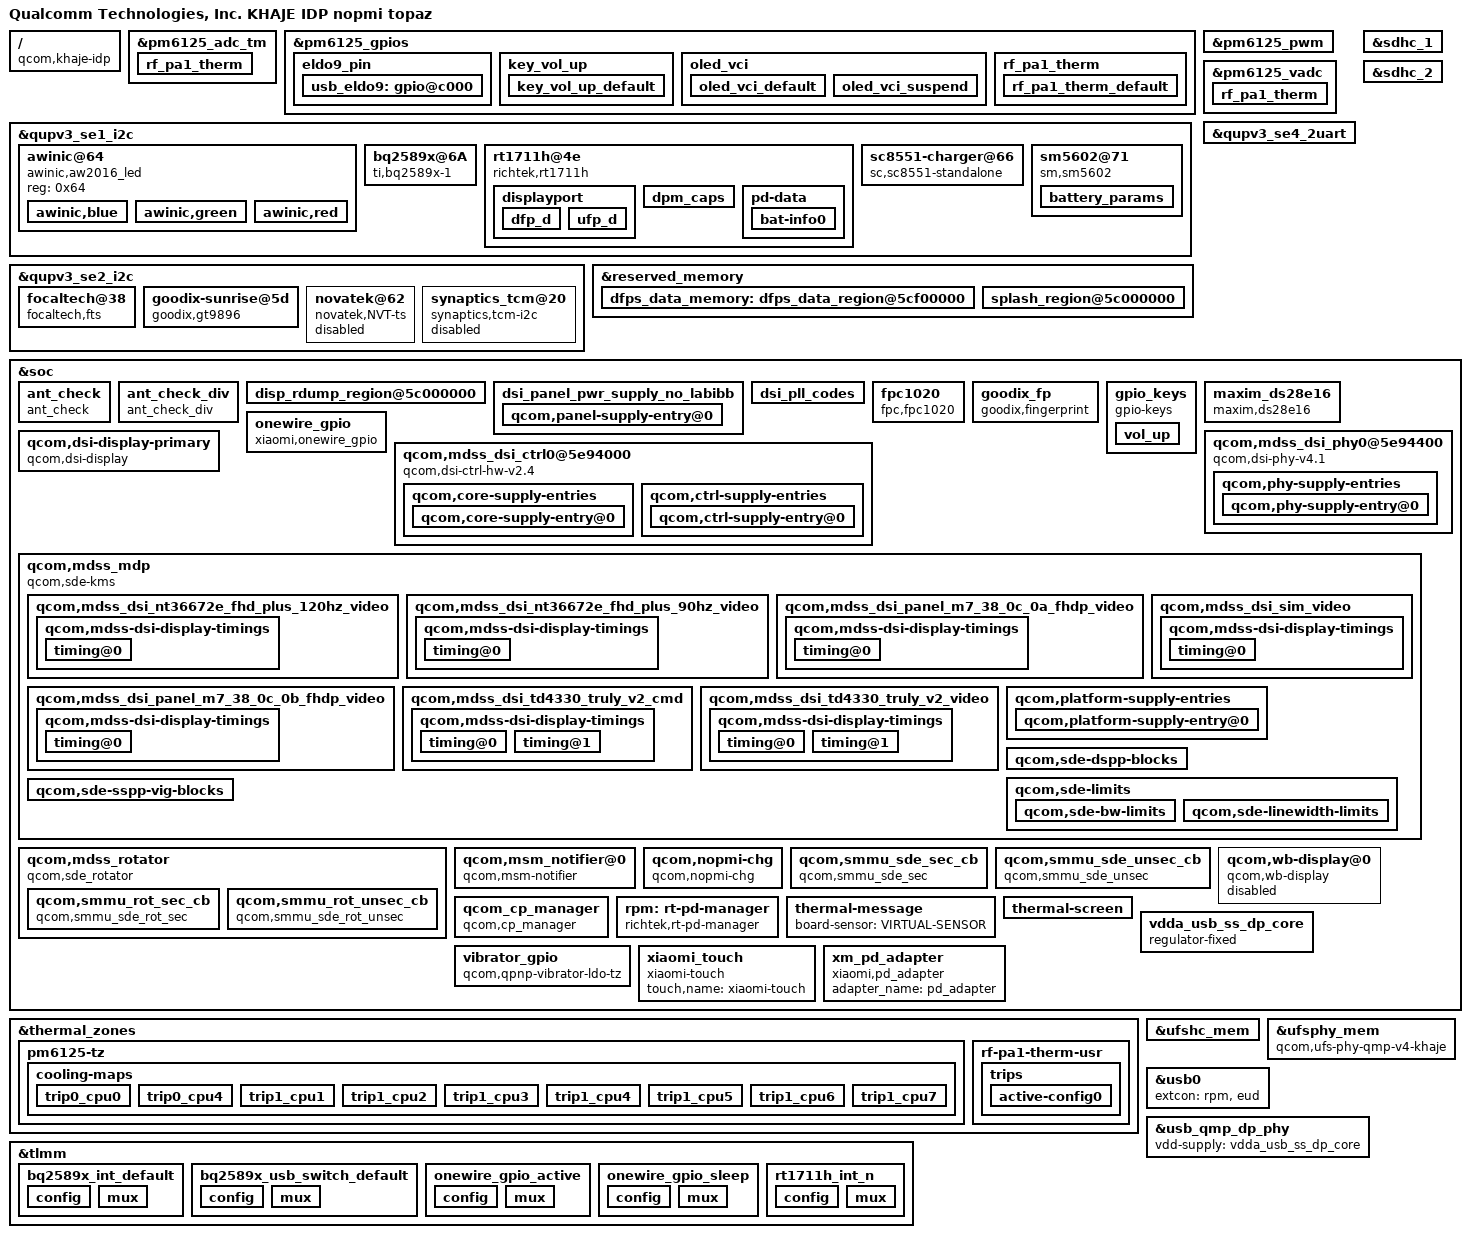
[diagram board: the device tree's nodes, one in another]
/dts-v1/;
// version: 17
// last_comp_version: 16
// boot_cpuid_phys: 0x0

/ {
    compatible = "qcom,khaje-idp", "qcom,khaje", "qcom,idp";
    model = "Qualcomm Technologies, Inc. KHAJE IDP nopmi topaz";
    qcom,board-id = <0x30022 0x0>;
    qcom,msm-id = <0x24A 0x10000>;
    qcom,pmic-id = <0x2D 0x0 0x0 0x0>;
};

&pm6125_adc_tm {
    status = "ok";
    rf_pa1_therm {
        io-channels = <&pm6125_vadc 0x55>;
        qcom,hw-settle-time-us = <0xC8>;
        qcom,ratiometric;
        reg = <0x3>;
    };
};

&pm6125_gpios {
    eldo9_pin {
        usb_eldo9: gpio@c000 {
            bias-disable;
            function = "normal";
            output-high;
            pins = "gpio1";
            power-source = <0x0>;
            qcom,drive-strength = <0x2>;
        };
    };
    key_vol_up {
        key_vol_up_default: key_vol_up_default {
            bias-pull-up;
            function = "normal";
            input-enable;
            pins = "gpio5";
            power-source = <0x0>;
        };
    };
    oled_vci {
        oled_vci_default: oled_vci_default {
            bias-disable;
            function = "normal";
            input-disable;
            output-high;
            pins = "gpio9";
            power-source = <0x0>;
            qcom,drive-strength = <0x2>;
        };
        oled_vci_suspend: oled_vci_suspend {
            bias-disable;
            function = "normal";
            input-disable;
            output-low;
            pins = "gpio9";
            power-source = <0x0>;
            qcom,drive-strength = <0x2>;
        };
    };
    rf_pa1_therm {
        rf_pa1_therm_default: rf_pa1_therm_default {
            bias-high-impedance;
            pins = "gpio7";
        };
    };
};

&pm6125_pwm {
    status = "ok";
};

&pm6125_vadc {
    pinctrl-0 = <&camera_therm_default &emmc_therm_default &rf_pa1_therm_default>;
    rf_pa1_therm {
        label = "rf_pa1_therm";
        qcom,hw-settle-time = <0xC8>;
        qcom,pre-scaling = <0x1 0x1>;
        qcom,ratiometric;
        reg = <0x55>;
    };
};

&qupv3_se1_i2c {
    #address-cells = <0x1>;
    #size-cells = <0x0>;
    status = "ok";
    awinic@64 {
        compatible = "awinic,aw2016_led";
        reg = <0x64>;
        awinic,blue {
            awinic,fall-time-ms = <0x6>;
            awinic,hold-time-ms = <0x0>;
            awinic,id = <0x2>;
            awinic,imax = <0x2>;
            awinic,led-current = <0x3>;
            awinic,max-brightness = <0xFF>;
            awinic,name = "blue";
            awinic,off-time-ms = <0x4>;
            awinic,rise-time-ms = <0x6>;
        };
        awinic,green {
            awinic,fall-time-ms = <0x6>;
            awinic,hold-time-ms = <0x0>;
            awinic,id = <0x1>;
            awinic,imax = <0x2>;
            awinic,led-current = <0x3>;
            awinic,max-brightness = <0xFF>;
            awinic,name = "green";
            awinic,off-time-ms = <0x4>;
            awinic,rise-time-ms = <0x6>;
        };
        awinic,red {
            awinic,fall-time-ms = <0x6>;
            awinic,hold-time-ms = <0x0>;
            awinic,id = <0x0>;
            awinic,imax = <0x2>;
            awinic,led-current = <0x3>;
            awinic,max-brightness = <0xFF>;
            awinic,name = "red";
            awinic,off-time-ms = <0x4>;
            awinic,rise-time-ms = <0x6>;
        };
    };
    bq2589x@6A {
        #address-cells = <0x1>;
        #io-channel-cells = <0x1>;
        #size-cells = <0x0>;
        compatible = "ti,bq2589x-1";
        interrupt-parent = <&tlmm>;
        interrupts = <0x69 0x0>;
        intr-gpio = <&tlmm 0x69 0x0>;
        io-channel-names = "ds_chip_ok", "fastcharge_mode", "fg_monitor_work", "mtbf_cur", "usb_real_type", "pd_active", "typec_cc_orientation", "typec_mode", "ffc_disable";
        io-channels = <&maxim_ds28e16 0x8D &sm5602 0xA4 &sm5602 0xAC &nopmi_chg 0x90 &nopmi_chg 0xA &nopmi_chg 0x4 &nopmi_chg 0x3 &nopmi_chg 0x1 &nopmi_chg 0xAB>;
        pinctrl-0 = <&bq2589x_int_default>;
        pinctrl-names = "default";
        reg = <0x6A>;
        ti,bq2589x,charge-current = <0x7D0>;
        ti,bq2589x,charge-current-1000 = <0x3E8>;
        ti,bq2589x,charge-current-1500 = <0x5DC>;
        ti,bq2589x,charge-current-3500 = <0xDAC>;
        ti,bq2589x,charge-current-500 = <0x1F4>;
        ti,bq2589x,charge-voltage = <0x1162>;
        ti,bq2589x,enable-auto-dpdm;
        ti,bq2589x,enable-ico;
        ti,bq2589x,enable-termination;
        ti,bq2589x,input-current-2000 = <0x7D0>;
        ti,bq2589x,term-current = <0x100>;
        ti,bq2589x,use-absolute-vindpm;
        ti,bq2589x,vbat-min-volt-to-tuneup = <0xBB8>;
        ti,bq2589x,vbus-volt-high-level = <0x21FC>;
        ti,bq2589x,vbus-volt-low-level = <0x1130>;
        usb-switch1 = <&tlmm 0x1F 0x0>;
    };
    rt1711h@4e {
        #io-channel-cells = <0x1>;
        compatible = "richtek,rt1711h";
        pinctrl-0 = <&rt1711h_int_n>;
        pinctrl-names = "default";
        reg = <0x4E>;
        rt-tcpc,name = "type_c_port0";
        rt-tcpc,role_def = <0x4>;
        rt-tcpc,rp_level = <0x0>;
        rt-tcpc,vconn_supply = <0x1>;
        rt1711pd,intr_gpio = <&tlmm 0x5D 0x0>;
        rt1711pd,intr_gpio_num = <0x5D>;
        status = "okay";
        tcpc-dual,supported_modes = <0x0>;
        displayport {
            1st_connection = "dfp_d";
            2nd_connection = "dfp_d";
            signal,dp_v13;
            typec,receptacle;
            dfp_d {
                pin_assignment,mode_c;
                pin_assignment,mode_d;
                pin_assignment,mode_e;
            };
            ufp_d {
            };
        };
        dpm_caps {
            attemp_discover_cable;
            attemp_discover_id;
            attemp_enter_dp_mode;
            dr_check = <0x0>;
            local_dr_data;
            local_dr_power;
            local_no_suspend;
            local_usb_comm;
            local_vconn_supply;
            pr_check = <0x0>;
        };
        pd-data {
            bat,nr = <0x1>;
            pd,charging_policy = <0x31>;
            pd,country_nr = <0x0>;
            pd,id-vdo-data = <0xD14029CF 0x0 0x17110000 0x61000000 0x0 0x41000000>;
            pd,id-vdo-size = <0x6>;
            pd,mfrs = "RichtekTCPC";
            pd,pid = <0x1711>;
            pd,sink-pdo-data = <0x190C8>;
            pd,sink-pdo-size = <0x1>;
            pd,source-cap-ext = [CF 29 11 17 00 00 00 00 00 00 00 00 00 00 00 00 00 00 00 00 00 00 00 02 00];
            pd,source-pdo-data = <0x19032>;
            pd,source-pdo-size = <0x1>;
            pd,vid = <0x29CF>;
            bat-info0 {
                bat,design_cap = <0xBB8>;
                bat,mfrs = "bat1";
                bat,pid = <0x1711>;
                bat,vid = <0x29CF>;
            };
        };
    };
    sc8551-charger@66 {
        #io-channel-cells = <0x1>;
        compatible = "sc,sc8551-standalone";
        irq-gpios = <&tlmm 0x54 0x0>;
        reg = <0x66>;
        sc,sc8551,ac-ovp-threshold = <0x11>;
        sc,sc8551,bat-ocp-alarm-threshold = <0x1D4C>;
        sc,sc8551,bat-ocp-threshold = <0x1F40>;
        sc,sc8551,bat-ovp-alarm-threshold = <0x1130>;
        sc,sc8551,bat-ovp-threshold = <0x11AD>;
        sc,sc8551,bat-therm-disable = <0x0>;
        sc,sc8551,bat-therm-threshold = <0x15>;
        sc,sc8551,bat-ucp-alarm-threshold = <0x7D0>;
        sc,sc8551,bus-ocp-alarm-threshold = <0xDAC>;
        sc,sc8551,bus-ocp-threshold = <0xEA6>;
        sc,sc8551,bus-ovp-alarm-threshold = <0x2AF8>;
        sc,sc8551,bus-ovp-threshold = <0x2EE0>;
        sc,sc8551,bus-therm-disable = <0x0>;
        sc,sc8551,bus-therm-threshold = <0x15>;
        sc,sc8551,die-therm-threshold = <0x7D>;
        sc,sc8551,sense-resistor-mohm = <0x5>;
    };
    sm5602@71 {
        #io-channel-cells = <0x1>;
        compatible = "sm,sm5602";
        io-channel-names = "ds_authen_result", "ds_romid", "ds_status", "ds_page0_data", "ds_chip_ok", "usb_real_type", "charging_enabled", "sc_battery_voltage", "ln_charging_enabled", "ln_battery_voltage", "charge_done";
        io-channels = <&maxim_ds28e16 0x84 &maxim_ds28e16 0x80 &maxim_ds28e16 0x81 &maxim_ds28e16 0x8A &maxim_ds28e16 0x8D &nopmi_chg 0xA &sc8551_standalone 0x76 &sc8551_standalone 0x96 &bq2589x 0x39>;
        reg = <0x71>;
        sm,aging_ctrl = <0x121>;
        sm,battery_table_num = <0x0>;
        sm,cycle_cfg = <0x7000>;
        sm,en_batt_det;
        sm,en_temp_ex;
        sm,fg_irq_set = <0x7FF>;
        sm,low_soc1 = <0x1>;
        sm,low_soc2 = <0xF>;
        sm,misc = <0x800>;
        sm,param_version = <0x5>;
        sm,rsns = <0x0>;
        sm,shutdown-delay-enable;
        sm,soc_decimal_rate = <0x0 0x26 0xA 0x23 0x14 0x21 0x1E 0x21 0x28 0x21 0x32 0x21 0x3C 0x21 0x46 0x1E 0x50 0x19 0x5A 0x14 0x5F 0xA>;
        sm,t_h_alarm_ex = <0x955F>;
        sm,t_h_alarm_in = <0x1>;
        sm,t_l_alarm_ex = <0xD632>;
        sm,t_l_alarm_in = <0x36>;
        sm,v_h_alarm = <0x1162>;
        sm,v_l_alarm = <0xD48>;
        battery_params {
            battery0,alpha = <0xCC>;
            battery0,battery_table0 = <0x1400 0x1B3D 0x1C5E 0x1D3A 0x1D80 0x1D8D 0x1D93 0x1DAA 0x1DFA 0x1E3E 0x1E77 0x1EB2 0x1F09 0x1F67 0x1FB3 0x1FE6 0x2046 0x20EB 0x21A1 0x2220 0x227A 0x2319 0x2360 0x24CC>;
            battery0,battery_table1 = <0x0 0x68 0x1F2 0x400 0x58A 0x798 0xAAC 0xCBA 0x1367 0x1B1A 0x22CD 0x2A80 0x3234 0x3756 0x39E7 0x3C78 0x419A 0x494E 0x5101 0x5623 0x59BB 0x60EB 0x6400 0x64E6>;
            battery0,battery_table2 = <0x141C 0x1011 0xE0F 0xC0D 0xB0B 0xA0B 0xA0A 0x909>;
            battery0,battery_type = <0x1162 0x0 0x26C9>;
            battery0,beta = <0x25>;
            battery0,curr_offset = <0x0>;
            battery0,curr_slope = <0x8080>;
            battery0,ext_temp_cal = <0x0 0x2 0x1 0x2 0x1 0x1 0x2 0x3 0x2 0x3>;
            battery0,fcm_offset = <0x52>;
            battery0,max_voltage_uv = <0x43E6D0>;
            battery0,mix_value = <0x3>;
            battery0,param_version = <0x1>;
            battery0,rs = <0x5F>;
            battery0,rs_value = <0x50 0x10A 0x3800 0x48>;
            battery0,tem_poff = <0xD48 0x64>;
            battery0,temp_cal = <0x0 0x6 0x1 0xB 0xFFFFFFFF 0x0 0x6 0x1 0x9 0x1>;
            battery0,temp_offset = <0x0 0xB 0x1 0x0 0x8 0xFFFFFFFF>;
            battery0,temp_std = <0x19>;
            battery0,thermal_table = <0x506E 0x4F35 0x4E07 0x4CC0 0x4B76 0x4A25 0x48BD 0x475D 0x45F5 0x4477 0x4304 0x4175 0x3FDE 0x3E4A 0x3CA2 0x3AF6 0x3945 0x378A 0x35CB 0x33FC 0x322B 0x3059 0x2E82 0x2CA0 0x2AC6 0x28C6 0x26E0 0x24EA 0x22E8 0x20EF 0x1EE7 0x1CEE 0x1AE8 0x18D0 0x16D6 0x14D0 0x12F3 0x10E4 0xEC4 0xCAC 0xAAC 0x8AC 0x6A9 0x49D 0x2A1 0x9BE9 0x9871 0x9278 0x9081 0x8E3B 0x8C8C 0x8AE1 0x893E 0x87A1 0x8605 0x8432 0x8262 0x809B 0x7ED9 0x7D1F 0x7B67 0x79B4 0x780B 0x766B 0x74D6 0x7342 0x71C0 0x7048 0x6EDC 0x6D78 0x6C25 0x6AD6 0x6991 0x6850 0x671A 0x65E6 0x64BC 0x6397 0x6274 0x615A 0x6049 0x5F3E 0x5E39 0x5D38 0x5C3C 0x5B4C 0x5A60 0x597E 0x58A6 0x57D2 0x5709 0x5644 0x5586 0x54CD 0x541A 0x5370 0x52C8 0x5226 0x5188 0x50F0 0x505D 0x4FCE 0x4F48 0x4EC6 0x4E46 0x4DCF 0x4D58 0x4CE9 0x4C7D 0x4C19 0x4BB6 0x4B58 0x4AFE 0x4AA8 0x4A56 0x4A09 0x49BC 0x4976 0x4932 0x48F0 0x48B1 0x4874 0x4839>;
            battery0,topoff_soc = <0x7 0x12C 0x64>;
            battery0,vit_period = <0x315A>;
            battery0,volt_cal = <0x8000>;
            battery1,alpha = <0xCC>;
            battery1,battery_table0 = <0x1400 0x1B45 0x1C46 0x1CEC 0x1D46 0x1D8C 0x1D97 0x1DDE 0x1E00 0x1E18 0x1E4D 0x1E8D 0x1EF2 0x1F60 0x1FCD 0x1FFD 0x2048 0x20CF 0x2137 0x221C 0x2263 0x2317 0x235B 0x24CC>;
            battery1,battery_table1 = <0x0 0x66 0x193 0x31B 0x4A3 0x730 0xB44 0xD4E 0x13FF 0x1BA6 0x233C 0x2AE2 0x32C8 0x3762 0x3A0E 0x3C9B 0x4175 0x497B 0x5101 0x5641 0x581C 0x60F0 0x6400 0x64E6>;
            battery1,battery_table2 = <0x1720 0x1218 0x1011 0xD0E 0xC0C 0xB0B 0xA0A 0xA0A>;
            battery1,battery_type = <0x1162 0x0 0x2700>;
            battery1,beta = <0x25>;
            battery1,curr_offset = <0x0>;
            battery1,curr_slope = <0x8080>;
            battery1,ext_temp_cal = <0x0 0x2 0x1 0x2 0x1 0x1 0x2 0x3 0x2 0x3>;
            battery1,fcm_offset = <0x67>;
            battery1,max_voltage_uv = <0x43E6D0>;
            battery1,mix_value = <0x3>;
            battery1,param_version = <0x2>;
            battery1,rs = <0x5F>;
            battery1,rs_value = <0x50 0x10A 0x3800 0x48>;
            battery1,tem_poff = <0xD48 0x64>;
            battery1,temp_cal = <0x0 0x6 0x1 0xB 0xFFFFFFFF 0x0 0x6 0x1 0x9 0x1>;
            battery1,temp_offset = <0x0 0xB 0x1 0x0 0x8 0xFFFFFFFF>;
            battery1,temp_std = <0x19>;
            battery1,thermal_table = <0x1D45 0x1A99 0x18FA 0x14E0 0x111E 0xD90 0x8B0 0x4E7 0x7A 0xF4E4 0xF21D 0xEE35 0xEAD5 0xE736 0xE3CF 0xDFEC 0xDC89 0xD9F2 0xD77F 0xD3F4 0xD13E 0xCF91 0xCC61 0xCA37 0xC81E 0xC5C3 0xC2D0 0xC069 0xBE17 0xBBE1 0xB9C6 0xB7C0 0xB5D3 0xB400 0xB242 0xB092 0xAEFD 0xAD7C 0xAC06 0xAAA6 0xA953 0xA814 0xA6DE 0xA5BE 0xA4A5 0xA39C 0xA2A1 0xA1B1 0xA0CB 0x9FF3 0x9F23 0x9E59 0x9D9A 0x9CE7 0x9C3B 0x9B95 0x9AF7 0x9A62 0x99D2 0x994B 0x98CB 0x984E 0x97D6 0x9765 0x96FA 0x9693 0x9631 0x95D3 0x9579 0x9523 0x94CF 0x9481 0x9435 0x93EC 0x93A6 0x9364 0x9325 0x92EA 0x92B1 0x927B 0x9245 0x9212 0x91E1 0x91B2 0x9185 0x915A 0x9132 0x910B 0x90E6 0x90C2 0x90A0 0x907E 0x905E 0x9040 0x9022 0x9006 0x8FEA 0x8FD0 0x8FB7 0x8FA0 0x8F8A>;
            battery1,topoff_soc = <0x7 0x12C 0x64>;
            battery1,vit_period = <0x315A>;
            battery1,volt_cal = <0x8000>;
            battery2,alpha = <0xCC>;
            battery2,battery_table0 = <0x1400 0x1B3D 0x1C5E 0x1D3A 0x1D80 0x1D8D 0x1D93 0x1DAA 0x1DFA 0x1E3E 0x1E77 0x1EB2 0x1F09 0x1F67 0x1FB3 0x1FE6 0x2046 0x20EB 0x21A1 0x2220 0x227A 0x2319 0x2360 0x24CC>;
            battery2,battery_table1 = <0x0 0x68 0x1F2 0x400 0x58A 0x798 0xAAC 0xCBA 0x1367 0x1B1A 0x22CD 0x2A80 0x3234 0x3756 0x39E7 0x3C78 0x419A 0x494E 0x5101 0x5623 0x59BB 0x60EB 0x6400 0x64E6>;
            battery2,battery_table2 = <0x140C 0x1011 0xE0F 0xC0D 0xB0B 0xA0B 0xA0A 0x909>;
            battery2,battery_type = <0x1162 0x0 0x2719>;
            battery2,beta = <0x25>;
            battery2,curr_offset = <0x0>;
            battery2,curr_slope = <0x8080>;
            battery2,ext_temp_cal = <0x0 0x2 0x1 0x2 0x1 0x1 0x2 0x3 0x2 0x3>;
            battery2,fcm_offset = <0x52>;
            battery2,max_voltage_uv = <0x43E6D0>;
            battery2,mix_value = <0x3>;
            battery2,param_version = <0x1>;
            battery2,rs = <0x5F>;
            battery2,rs_value = <0x50 0x10A 0x3800 0x48>;
            battery2,tem_poff = <0xD48 0x64>;
            battery2,temp_cal = <0x0 0x6 0x1 0xB 0xFFFFFFFF 0x0 0x6 0x1 0x9 0x1>;
            battery2,temp_offset = <0x0 0xB 0x1 0x0 0x8 0xFFFFFFFF>;
            battery2,temp_std = <0x19>;
            battery2,thermal_table = <0x504E 0x4F35 0x4E27 0x4CC0 0x4B56 0x4A21 0x48DD 0x477D 0x45D5 0x4447 0x42A4 0x4125 0x3FC5 0x3F4A 0x3D02 0x3AE5 0x38C5 0x3689 0x344B 0x322B 0x3019 0x2E39 0x2C60 0x2AA0 0x2926 0x27A0 0x2640 0x24B9 0x2340 0x21CF 0x2087 0x1F77 0x1E3E 0x1D00 0x1BB7 0x1A60 0x1906 0x17AD 0x1645 0x14E0 0x1376 0x1209 0x109E 0xF34 0xDC8 0xC5E 0xAF6 0x990 0x829 0x6C4 0x55F 0x3FE 0x2A3 0x146 0x9EE 0x5BE1 0x5BD1 0x5BD0 0x5BD0 0x5CA3 0x5D1C 0x5D81 0x5DEF 0x5E70 0x5EFB 0x5F98 0x6047 0x6109 0x61D9 0x62C1 0x63C2 0x64CF 0x65F4>;
            battery2,topoff_soc = <0x7 0x15E>;
            battery2,vit_period = <0x325A>;
            battery2,volt_cal = <0x8000>;
        };
    };
};

&qupv3_se2_i2c {
    qcom,i2c-touch-active = "synaptics,tcm-i2c";
    qcom,touch-active = "goodix,gt9896";
    status = "okay";
    focaltech@38 {
        compatible = "focaltech,fts";
        focaltech,avdd-gpio = <&tlmm 0x24 0x0>;
        focaltech,display-coords = <0x0 0x0 0x2A2F 0x5DBF>;
        focaltech,irq-gpio = <&tlmm 0x50 0x2>;
        focaltech,max-touch-number = <0xA>;
        focaltech,reset-gpio = <&tlmm 0x56 0x1>;
        interrupt-parent = <&tlmm>;
        interrupts = <0x50 0x2>;
        panel = <&dsi_panel_m7_38_0c_0a_fhdp_video>;
        pinctrl-0 = <&ts_int_active &ts_reset_active &ts_avdd>;
        pinctrl-1 = <&ts_int_suspend &ts_reset_suspend>;
        pinctrl-2 = <&ts_release>;
        pinctrl-names = "pmx_ts_active", "pmx_ts_suspend", "pmx_ts_release";
        reg = <0x38>;
        status = "okay";
    };
    goodix-sunrise@5d {
        compatible = "goodix,gt9896";
        goodix,avdd-gpio = <&tlmm 0x24 0x0>;
        goodix,irq-flags = <0x2>;
        goodix,irq-gpio = <&tlmm 0x50 0x2>;
        goodix,panel-max-w = <0xFF>;
        goodix,panel-max-x = <0x2A30>;
        goodix,panel-max-y = <0x5DC0>;
        goodix,reset-gpio = <&tlmm 0x56 0x1>;
        interrupt-parent = <&tlmm>;
        interrupts = <0x50 0x2>;
        panel = <&dsi_panel_m7_38_0c_0b_fhdp_video>;
        pinctrl-0 = <&ts_int_active &ts_reset_active &ts_avdd>;
        pinctrl-1 = <&ts_int_suspend &ts_reset_suspend>;
        pinctrl-2 = <&ts_release>;
        pinctrl-names = "pmx_ts_active", "pmx_ts_suspend", "pmx_ts_release";
        reg = <0x5D>;
        status = "okay";
    };
    novatek@62 {
        interrupt-parent = <&tlmm>;
        interrupts = <0x50 0x2008>;
        novatek,irq-gpio = <&tlmm 0x50 0x2008>;
        novatek,reset-gpio = <&tlmm 0x56 0x0>;
        pinctrl-0 = <&ts_int_active &ts_reset_active>;
        pinctrl-1 = <&ts_int_suspend &ts_reset_suspend>;
        pinctrl-2 = <&ts_release>;
        pinctrl-names = "pmx_ts_active", "pmx_ts_suspend", "pmx_ts_release";
        reg = <0x62>;
        status = "disabled";
        compatible = "novatek,NVT-ts";
        panel = <&dsi_nt36672e_fhd_plus_90hz_video &dsi_nt36672e_fhd_plus_120hz_video>;
    };
    synaptics_tcm@20 {
        compatible = "synaptics,tcm-i2c";
        interrupt-parent = <&tlmm>;
        interrupts = <0x50 0x2008>;
        pinctrl-0 = <&ts_int_active &ts_reset_active>;
        pinctrl-1 = <&ts_int_suspend &ts_reset_suspend>;
        pinctrl-2 = <&ts_release>;
        pinctrl-names = "pmx_ts_active", "pmx_ts_suspend", "pmx_ts_release";
        reg = <0x20>;
        synaptics,extend_report;
        synaptics,firmware-name = "synaptics_firmware_k.img";
        synaptics,irq-gpio = <&tlmm 0x50 0x2008>;
        synaptics,irq-on-state = <0x0>;
        synaptics,power-delay-ms = <0xC8>;
        synaptics,reset-active-ms = <0x14>;
        synaptics,reset-delay-ms = <0xC8>;
        synaptics,reset-gpio = <&tlmm 0x56 0x0>;
        synaptics,reset-on-state = <0x0>;
        synaptics,ubl-i2c-addr = <0x20>;
        panel = <&dsi_td4330_truly_v2_video &dsi_td4330_truly_v2_cmd>;
        status = "disabled";
    };
};

&qupv3_se4_2uart {
    status = "ok";
};

&reserved_memory {
    dfps_data_memory: dfps_data_region@5cf00000 {
        label = "dfps_data_region";
        reg = <0x0 0x5CF00000 0x0 0x100000>;
    };
    splash_region@5c000000 {
        label = "cont_splash_region";
        reg = <0x0 0x5C000000 0x0 0xF00000>;
    };
};

&sdhc_1 {
    pinctrl-0 = <&sdc1_on>;
    pinctrl-1 = <&sdc1_off>;
    pinctrl-names = "default", "sleep";
    qcom,vdd-current-level = <0x0 0x8B290>;
    qcom,vdd-io-always-on;
    qcom,vdd-io-current-level = <0x0 0x4F588>;
    qcom,vdd-io-lpm-sup;
    qcom,vdd-io-voltage-level = <0x1B7740 0x1B7740>;
    qcom,vdd-voltage-level = <0x2D2A80 0x2D2A80>;
    status = "ok";
    vdd-io-supply = <&L11A>;
    vdd-supply = <&L24A>;
};

&sdhc_2 {
    cd-gpios = <&tlmm 0x58 0x0>;
    pinctrl-0 = <&sdc2_on>;
    pinctrl-1 = <&sdc2_off>;
    pinctrl-names = "default", "sleep";
    qcom,vdd-current-level = <0x0 0xC3500>;
    qcom,vdd-io-bias-current-level = <0x0 0x1770>;
    qcom,vdd-io-bias-voltage-level = <0x132A40 0x132A40>;
    qcom,vdd-io-current-level = <0x0 0x55F0>;
    qcom,vdd-io-voltage-level = <0x1B7740 0x2D2A80>;
    qcom,vdd-voltage-level = <0x2D2A80 0x2D2A80>;
    status = "ok";
    vdd-io-bias-supply = <&L7A>;
    vdd-io-supply = <&L5A>;
    vdd-supply = <&L22A>;
};

&soc {
    ant_check {
        ant_check_gpio = <&tlmm 0x6B 0x0>;
        compatible = "ant_check";
        interrupt-parent = <&tlmm>;
        pinctrl-0 = <&ant_check_default>;
        pinctrl-names = "default";
    };
    ant_check_div {
        ant_check_div_gpio = <&tlmm 0x19 0x0>;
        compatible = "ant_check_div";
        interrupt-parent = <&tlmm>;
        pinctrl-0 = <&ant_check_div_default>;
        pinctrl-names = "default";
    };
    disp_rdump_region@5c000000 {
        label = "disp_rdump_region";
        reg = <0x0 0x5C000000 0x0 0xF00000>;
    };
    dsi_panel_pwr_supply_no_labibb {
        #address-cells = <0x1>;
        #size-cells = <0x0>;
        qcom,panel-supply-entry@0 {
            qcom,supply-disable-load = <0x50>;
            qcom,supply-enable-load = <0xF230>;
            qcom,supply-max-voltage = <0x1B7740>;
            qcom,supply-min-voltage = <0x1B7740>;
            qcom,supply-name = "vddio";
            qcom,supply-post-on-sleep = <0x14>;
            reg = <0x0>;
        };
    };
    dsi_pll_codes {
        label = "dsi_pll_codes";
        reg = <0x0 0x0 0x0 0x0 0x0 0x0 0x0 0x0 0x0 0x0 0x0 0x0 0x0 0x0 0x0 0x0 0x0 0x0 0x0 0x0 0x0 0x0 0x0 0x0 0x0 0x0 0x0 0x0 0x0 0x0 0x0 0x0 0x0 0x0 0x0 0x0 0x0 0x0 0x0 0x0 0x0 0x0 0x0 0x0 0x0 0x0 0x0 0x0 0x0 0x0 0x0 0x0 0x0 0x0 0x0 0x0 0x0 0x0 0x0 0x0 0x0 0x0 0x0 0x0 0x0 0x0 0x0 0x0 0x0 0x0 0x0 0x0 0x0 0x0 0x0 0x0 0x0 0x0 0x0 0x0 0x0 0x0 0x0 0x0 0x0 0x0 0x0 0x0 0x0 0x0 0x0 0x0 0x0 0x0 0x0 0x0 0x0 0x0 0x0 0x0 0x0 0x0 0x0 0x0 0x0 0x0 0x0 0x0 0x0 0x0 0x0 0x0 0x0 0x0 0x0 0x0 0x0 0x0 0x0 0x0 0x0 0x0 0x0 0x0 0x0 0x0 0x0 0x0>;
    };
    fpc1020 {
        compatible = "fpc,fpc1020";
        fpc,enable-on-boot;
        fpc,gpio_irq = <&tlmm 0x53 0x0>;
        fpc,gpio_rst = <&tlmm 0x68 0x0>;
        fpc,gpio_vdd_for_plsensor = <&tlmm 0x41 0x0>;
        interrupt-parent = <&tlmm>;
        interrupts = <0x53 0x0>;
        pinctrl-0 = <&msm_gpio_104>;
        pinctrl-1 = <&msm_gpio_104_output_high>;
        pinctrl-2 = <&msm_gpio_83>;
        pinctrl-names = "fpc1020_reset_reset", "fpc1020_reset_active", "fpc1020_irq_active";
        status = "ok";
        vcc_spi-supply = <&pm6125_l9>;
        vdd_ana-supply = <&pm6125_l9>;
        vdd_io-supply = <&pm6125_l9>;
    };
    goodix_fp {
        compatible = "goodix,fingerprint";
        fp-gpio-irq = <&tlmm 0x53 0x0>;
        fp-gpio-pwr = <&tlmm 0x41 0x0>;
        fp-gpio-reset = <&tlmm 0x68 0x0>;
        interrupt = <0x53 0x0>;
        interrupt-parent = <&tlmm>;
        pinctrl-0 = <&msm_gpio_104>;
        pinctrl-1 = <&msm_gpio_104_output_high>;
        pinctrl-2 = <&msm_gpio_65>;
        pinctrl-3 = <&msm_gpio_65_output_high>;
        pinctrl-names = "goodix_reset_outputlow", "goodix_reset_outputhigh", "goodix_pwr_outputlow", "goodix_pwr_outputhigh";
        status = "okay";
        vcc_ana_supply = <&pm6125_l9>;
        vcc_spi_supply = <&pm6125_l9>;
        vdd_io-supply = <&pm6125_l9>;
    };
    gpio_keys {
        compatible = "gpio-keys";
        label = "gpio-keys";
        pinctrl-0 = <&key_vol_up_default>;
        pinctrl-names = "default";
        vol_up {
            debounce-interval = <0xF>;
            gpio-key,wakeup;
            gpios = <&pm6125_gpios 0x5 0x1>;
            label = "volume_up";
            linux,can-disable;
            linux,code = <0x73>;
            linux,input-type = <0x1>;
        };
    };
    maxim_ds28e16 {
        #io-channel-cells = <0x1>;
        compatible = "maxim,ds28e16";
        label = "max_ds28e16";
        maxim,version = <0x1>;
        status = "ok";
    };
    onewire_gpio {
        compatible = "xiaomi,onewire_gpio";
        label = "xm_onewire";
        mi,onewire-gpio-cfg-addr = <0x96C000 0x4>;
        pinctrl-0 = <&onewire_gpio_active>;
        pinctrl-1 = <&onewire_gpio_sleep>;
        pinctrl-names = "onewire_active", "onewire_sleep";
        status = "ok";
        xiaomi,gpio_number = <0x6C>;
        xiaomi,ow_gpio = <&tlmm 0x6C 0x0>;
        xiaomi,version = <0x1>;
    };
    qcom,dsi-display-primary {
        clock-names = "pll_byte_clk0", "pll_dsi_clk0", "mdp_core_clk";
        clocks = <&mdss_dsi_phy0 0x0 &mdss_dsi_phy0 0x1 &dispcc 0x8>;
        compatible = "qcom,dsi-display";
        label = "primary";
        pinctrl-0 = <&sde_dsi_active &sde_te_active>;
        pinctrl-1 = <&sde_dsi_suspend &sde_te_suspend>;
        pinctrl-names = "panel_active", "panel_suspend";
        qcom,dsi-ctrl = <&mdss_dsi0>;
        qcom,dsi-default-panel = <&dsi_panel_m7_38_0c_0a_fhdp_video>;
        qcom,dsi-phy = <&mdss_dsi_phy0>;
        qcom,mdp = <&mdss_mdp>;
        qcom,panel-te-source = <0x0>;
        qcom,platform-te-gpio = <&tlmm 0x51 0x0>;
        vddio-supply = <&L9A>;
    };
    qcom,mdss_dsi_ctrl0@5e94000 {
        cell-index = <0x0>;
        clock-names = "byte_clk", "byte_clk_rcg", "byte_intf_clk", "pixel_clk", "pixel_clk_rcg", "esc_clk";
        clocks = <&dispcc 0x2 &dispcc 0x3 &dispcc 0x5 &dispcc 0xC &dispcc 0xD &dispcc 0x6>;
        compatible = "qcom,dsi-ctrl-hw-v2.4";
        frame-threshold-time-us = <0x3E8>;
        interrupt-parent = <&mdss_mdp>;
        interrupts = <0x4 0x0>;
        label = "dsi-ctrl-0";
        refgen-supply = <&refgen>;
        reg = <0x5E94000 0x400 0x5F08000 0x4 0x5E6B800 0x300>;
        reg-names = "dsi_ctrl", "disp_cc_base", "mdp_intf_base";
        vdda-1p2-supply = <&L18A>;
        qcom,core-supply-entries {
            #address-cells = <0x1>;
            #size-cells = <0x0>;
            qcom,core-supply-entry@0 {
                qcom,supply-disable-load = <0x0>;
                qcom,supply-enable-load = <0x0>;
                qcom,supply-max-voltage = <0x0>;
                qcom,supply-min-voltage = <0x0>;
                qcom,supply-name = "refgen";
                reg = <0x0>;
            };
        };
        qcom,ctrl-supply-entries {
            #address-cells = <0x1>;
            #size-cells = <0x0>;
            qcom,ctrl-supply-entry@0 {
                qcom,supply-disable-load = <0x0>;
                qcom,supply-enable-load = <0x5528>;
                qcom,supply-max-voltage = <0x124F80>;
                qcom,supply-min-voltage = <0x124F80>;
                qcom,supply-name = "vdda-1p2";
                reg = <0x0>;
            };
        };
    };
    qcom,mdss_dsi_phy0@5e94400 {
        #clock-cells = <0x1>;
        cell-index = <0x0>;
        compatible = "qcom,dsi-phy-v4.1";
        label = "dsi-phy-0";
        memory-region = <&dfps_data_memory>;
        pll-label = "dsi_pll_5nm";
        pll_codes_region = <&dsi_pll_codes_data>;
        qcom,dsi-pll-ssc-en;
        qcom,dsi-pll-ssc-mode = "down-spread";
        qcom,platform-lane-config = <0xA0A 0xA0A 0xA0A 0xA0A 0x8A8A>;
        qcom,platform-regulator-settings = [1D 1D 1D 1D 1D];
        qcom,platform-strength-ctrl = [55 03 55 03 55 03 55 03 55 00];
        reg = <0x5E94400 0x800 0x5E94900 0x264 0x5E94200 0x100>;
        reg-names = "dsi_phy", "pll_base", "dyn_refresh_base";
        vdda-0p9-supply = <&L4A>;
        qcom,phy-supply-entries {
            #address-cells = <0x1>;
            #size-cells = <0x0>;
            qcom,phy-supply-entry@0 {
                qcom,supply-disable-load = <0x0>;
                qcom,supply-enable-load = <0x8CA0>;
                qcom,supply-max-voltage = <0xD6D80>;
                qcom,supply-min-voltage = <0xD6D80>;
                qcom,supply-name = "vdda-0p9";
                reg = <0x0>;
            };
        };
    };
    qcom,mdss_mdp {
        #interrupt-cells = <0x1>;
        #list-cells = <0x1>;
        #power-domain-cells = <0x0>;
        clock-max-rate = <0x0 0x0 0x0 0x0 0x2160EC00 0x124F800 0x2160EC00>;
        clock-names = "gcc_bus", "throttle_clk", "div_clk", "iface_clk", "core_clk", "vsync_clk", "lut_clk";
        clock-rate = <0x0 0x0 0x0 0x0 0x16D41DC0 0x124F800 0x16D41DC0>;
        clocks = <&gcc 0x3E &gcc 0x40 &gcc 0x3D &dispcc 0x0 &dispcc 0x8 &dispcc 0x12 &dispcc 0xA>;
        compatible = "qcom,sde-kms";
        connectors = <&sde_dsi &smmu_sde_sec &smmu_sde_unsec>;
        interconnect-names = "qcom,sde-data-bus0", "qcom,sde-reg-bus";
        interconnects = <&mmrt_virt 0xE &bimc 0x200 &bimc 0x0 &config_noc 0x212>;
        interrupt-controller;
        interrupts = <0x0 0xBA 0x4>;
        qcom,sde-axi-bus-width = <0x10>;
        qcom,sde-cdp-setting = <0x1 0x1 0x1 0x0>;
        qcom,sde-csc-type = "csc-10bit";
        qcom,sde-ctl-display-pref = "primary";
        qcom,sde-ctl-off = <0x2000>;
        qcom,sde-ctl-size = <0x1DC>;
        qcom,sde-danger-lut = <0xFF 0xFFFF 0x0 0x0 0xFFFF>;
        qcom,sde-dither-off = <0x30E0>;
        qcom,sde-dither-size = <0x20>;
        qcom,sde-dither-version = <0x10000>;
        qcom,sde-dram-channels = <0x1>;
        qcom,sde-dsc-off = <0x81000>;
        qcom,sde-dsc-size = <0x140>;
        qcom,sde-dspp-off = <0x55000>;
        qcom,sde-dspp-rc-mem-size = <0xAA0>;
        qcom,sde-dspp-rc-off = <0x15800>;
        qcom,sde-dspp-rc-size = <0x100>;
        qcom,sde-dspp-rc-version = <0x10000>;
        qcom,sde-dspp-size = <0x1800>;
        qcom,sde-dspp-top-off = <0x1300>;
        qcom,sde-dspp-top-size = <0x80>;
        qcom,sde-has-cdp;
        qcom,sde-has-dim-layer;
        qcom,sde-has-idle-pc;
        qcom,sde-highest-bank-bit = <0x1>;
        qcom,sde-ib-bw-vote = <0x249F00 0x0 0x186A00>;
        qcom,sde-intf-off = <0x0 0x6B800>;
        qcom,sde-intf-size = <0x2C0>;
        qcom,sde-intf-tear-irq-off = <0x0 0x6E800>;
        qcom,sde-intf-type = "none", "dsi";
        qcom,sde-len = <0x494>;
        qcom,sde-max-bw-high-kbps = <0x419CE0>;
        qcom,sde-max-bw-low-kbps = <0x30D400>;
        qcom,sde-max-per-pipe-bw-high-kbps = <0x30D400 0x30D400>;
        qcom,sde-max-per-pipe-bw-kbps = <0x30D400 0x30D400>;
        qcom,sde-min-core-ib-kbps = <0x249F00>;
        qcom,sde-min-dram-ib-kbps = <0x186A00>;
        qcom,sde-min-llcc-ib-kbps = <0x0>;
        qcom,sde-mixer-blend-op-off = <0x20 0x38 0x50 0x68 0x80 0x98 0xB0 0xC8 0xE0 0xF8 0x110>;
        qcom,sde-mixer-blendstages = <0x4>;
        qcom,sde-mixer-display-pref = "primary";
        qcom,sde-mixer-linewidth = <0x800>;
        qcom,sde-mixer-off = <0x45000>;
        qcom,sde-mixer-pair-mask = <0x0>;
        qcom,sde-mixer-size = <0x320>;
        qcom,sde-mixer-stage-base-layer;
        qcom,sde-num-mnoc-ports = <0x1>;
        qcom,sde-num-nrt-paths = <0x0>;
        qcom,sde-off = <0x1000>;
        qcom,sde-panic-per-pipe;
        qcom,sde-pp-off = <0x71000>;
        qcom,sde-pp-size = <0xD4>;
        qcom,sde-qos-cpu-dma-latency = <0x12C>;
        qcom,sde-qos-cpu-irq-latency = <0x12C>;
        qcom,sde-qos-cpu-mask = <0x3>;
        qcom,sde-qos-lut-linear = <0x0 0x112222 0x22335777>;
        qcom,sde-qos-lut-macrotile = <0x0 0x112233 0x44556677>;
        qcom,sde-qos-lut-macrotile-qseed = <0x0 0x112233 0x66777777>;
        qcom,sde-qos-lut-nrt = <0x0 0x0 0x0>;
        qcom,sde-qseed-scalar-version = <0x3000>;
        qcom,sde-qseed-sw-lib-rev = "qseedv3lite";
        qcom,sde-reg-bus,vectors-KBps = <0x0 0x0 0x0 0x12C00 0x0 0x249F0 0x0 0x493E0>;
        qcom,sde-safe-lut-linear = <0x0 0xFFF0>;
        qcom,sde-safe-lut-macrotile = <0x0 0xFF00>;
        qcom,sde-safe-lut-macrotile-qseed = <0x0 0xFF00>;
        qcom,sde-safe-lut-nrt = <0x0 0xFFFF>;
        qcom,sde-secure-sid-mask = <0x421>;
        qcom,sde-smart-dma-rev = "smart_dma_v2p5";
        qcom,sde-sspp-clk-ctrl = <0x2AC 0x0 0x2AC 0x8>;
        qcom,sde-sspp-csc-off = <0x1A00>;
        qcom,sde-sspp-excl-rect = <0x1 0x1>;
        qcom,sde-sspp-linewidth = <0x870>;
        qcom,sde-sspp-off = <0x5000 0x25000>;
        qcom,sde-sspp-qseed-off = <0xA00>;
        qcom,sde-sspp-smart-dma-priority = <0x2 0x1>;
        qcom,sde-sspp-src-size = <0x1F8>;
        qcom,sde-sspp-type = "vig", "dma";
        qcom,sde-sspp-xin-id = <0x0 0x1>;
        qcom,sde-ubwc-static = <0x11F>;
        qcom,sde-ubwc-swizzle = <0x7>;
        qcom,sde-ubwc-version = <0x10000000>;
        qcom,sde-vbif-id = <0x0>;
        qcom,sde-vbif-memtype-0 = <0x3 0x3 0x3 0x3 0x3 0x3 0x3 0x3>;
        qcom,sde-vbif-memtype-1 = <0x3 0x3 0x3 0x3 0x3 0x3>;
        qcom,sde-vbif-off = <0x0>;
        qcom,sde-vbif-qos-nrt-remap = <0x3 0x3 0x3 0x3 0x3 0x3 0x3 0x3 0x3 0x3 0x3 0x3 0x3 0x3 0x3 0x3>;
        qcom,sde-vbif-qos-rt-remap = <0x3 0x3 0x4 0x4 0x5 0x5 0x6 0x6 0x3 0x3 0x4 0x4 0x5 0x5 0x6 0x6>;
        qcom,sde-vbif-size = <0x2008>;
        reg = <0x5E00000 0x8F030 0x5EB0000 0x2008 0x5E8F000 0x30>;
        reg-names = "mdp_phys", "vbif_phys", "sid_phys";
        sde-vdd-supply = <&mdss_core_gdsc>;
        qcom,mdss_dsi_nt36672e_fhd_plus_120hz_video {
            pwms = <&pm6125_pwm 0x0 0x0>;
            qcom,adjust-timer-wakeup-ms = <0x1>;
            qcom,bl-pmic-pwm-period-usecs = <0x64>;
            qcom,dsi-ctrl-num = <0x0>;
            qcom,dsi-phy-num = <0x0>;
            qcom,dsi-select-clocks = "pll_byte_clk0", "pll_dsi_clk0";
            qcom,esd-check-enabled;
            qcom,mdss-dsi-bl-max-level = <0xFFF>;
            qcom,mdss-dsi-bl-min-level = <0x1>;
            qcom,mdss-dsi-bl-pmic-control-type = "bl_ctrl_pwm";
            qcom,mdss-dsi-bllp-eof-power-mode;
            qcom,mdss-dsi-bllp-power-mode;
            qcom,mdss-dsi-border-color = <0x0>;
            qcom,mdss-dsi-bpp = <0x18>;
            qcom,mdss-dsi-dma-trigger = "trigger_sw";
            qcom,mdss-dsi-lane-0-state;
            qcom,mdss-dsi-lane-1-state;
            qcom,mdss-dsi-lane-2-state;
            qcom,mdss-dsi-lane-3-state;
            qcom,mdss-dsi-mdp-trigger = "none";
            qcom,mdss-dsi-panel-blackness-level = <0x1361>;
            qcom,mdss-dsi-panel-hdr-color-primaries = <0x3A98 0x3E80 0x83D6 0x3DB8 0x33C2 0x8692 0x1D4C 0xBB8>;
            qcom,mdss-dsi-panel-hdr-enabled;
            qcom,mdss-dsi-panel-name = "nt36672e fhd plus 120Hz Video panel";
            qcom,mdss-dsi-panel-peak-brightness = <0x626B50>;
            qcom,mdss-dsi-panel-status-check-mode = "reg_read";
            qcom,mdss-dsi-panel-status-command = <0x6010001 0x10A>;
            qcom,mdss-dsi-panel-status-command-state = "dsi_lp_mode";
            qcom,mdss-dsi-panel-status-read-length = <0x1>;
            qcom,mdss-dsi-panel-status-value = <0x9C>;
            qcom,mdss-dsi-panel-type = "dsi_video_mode";
            qcom,mdss-dsi-reset-sequence = <0x1 0xA 0x0 0xA 0x1 0xA>;
            qcom,mdss-dsi-stream = <0x0>;
            qcom,mdss-dsi-traffic-mode = "burst_mode";
            qcom,mdss-dsi-tx-eot-append;
            qcom,mdss-dsi-virtual-channel-id = <0x0>;
            qcom,panel-supply-entries = <&dsi_panel_pwr_supply_no_labibb>;
            qcom,platform-reset-gpio = <&tlmm 0x52 0x0>;
            qcom,mdss-dsi-display-timings {
                timing@0 {
                    qcom,compression-mode = "dsc";
                    qcom,default-topology-index = <0x0>;
                    qcom,display-topology = <0x1 0x1 0x1>;
                    qcom,mdss-dsc-bit-per-component = <0x8>;
                    qcom,mdss-dsc-bit-per-pixel = <0x8>;
                    qcom,mdss-dsc-block-prediction-enable;
                    qcom,mdss-dsc-slice-height = <0x8>;
                    qcom,mdss-dsc-slice-per-pkt = <0x1>;
                    qcom,mdss-dsc-slice-width = <0x21C>;
                    qcom,mdss-dsi-h-back-porch = <0x3C>;
                    qcom,mdss-dsi-h-front-porch = <0x4C>;
                    qcom,mdss-dsi-h-pulse-width = <0xA>;
                    qcom,mdss-dsi-h-sync-skew = <0x0>;
                    qcom,mdss-dsi-off-command = <0x5010000 0x10000128 0x5010000 0x32000110>;
                    qcom,mdss-dsi-off-command-state = "dsi_lp_mode";
                    qcom,mdss-dsi-on-command = [15 01 00 00 00 00 02 FB 01 15 01 00 00 00 00 02 B0 00 15 01 00 00 00 00 02 C0 03 39 01 00 00 00 00 11 C1 89 28 00 08 00 AA 02 0E 00 2B 00 07 0D B7 0C B7 39 01 00 00 00 00 03 C2 1B A0 15 01 00 00 00 00 02 FF 20 15 01 00 00 00 00 02 FB 01 15 01 00 00 00 00 02 01 66 15 01 00 00 00 00 02 06 40 15 01 00 00 00 00 02 07 38 15 01 00 00 00 00 02 2F 83 15 01 00 00 00 00 02 69 91 15 01 00 00 00 00 02 95 D1 15 01 00 00 00 00 02 96 D1 15 01 00 00 00 00 02 F2 64 15 01 00 00 00 00 02 F4 64 15 01 00 00 00 00 02 F6 64 15 01 00 00 00 00 02 F8 64 15 01 00 00 00 00 02 89 1C 15 01 00 00 00 00 02 8A 1C 15 01 00 00 00 00 02 8B 1C 15 01 00 00 00 00 02 8C 1C 15 01 00 00 00 00 02 FF 24 15 01 00 00 00 00 02 FB 01 15 01 00 00 00 00 02 01 0F 15 01 00 00 00 00 02 03 0C 15 01 00 00 00 00 02 05 1D 15 01 00 00 00 00 02 08 2F 15 01 00 00 00 00 02 09 2E 15 01 00 00 00 00 02 0A 2D 15 01 00 00 00 00 02 0B 2C 15 01 00 00 00 00 02 11 17 15 01 00 00 00 00 02 12 13 15 01 00 00 00 00 02 13 15 15 01 00 00 00 00 02 15 14 15 01 00 00 00 00 02 16 16 15 01 00 00 00 00 02 17 18 15 01 00 00 00 00 02 1B 01 15 01 00 00 00 00 02 1D 1D 15 01 00 00 00 00 02 20 2F 15 01 00 00 00 00 02 21 2E 15 01 00 00 00 00 02 22 2D 15 01 00 00 00 00 02 23 2C 15 01 00 00 00 00 02 29 17 15 01 00 00 00 00 02 2A 13 15 01 00 00 00 00 02 2B 15 15 01 00 00 00 00 02 2F 14 15 01 00 00 00 00 02 30 16 15 01 00 00 00 00 02 31 18 15 01 00 00 00 00 02 32 04 15 01 00 00 00 00 02 34 10 15 01 00 00 00 00 02 35 1F 15 01 00 00 00 00 02 36 1F 15 01 00 00 00 00 02 4D 14 15 01 00 00 00 00 02 4E 36 15 01 00 00 00 00 02 4F 36 15 01 00 00 00 00 02 53 36 15 01 00 00 00 00 02 71 30 15 01 00 00 00 00 02 79 11 15 01 00 00 00 00 02 7A 82 15 01 00 00 00 00 02 7B 8F 15 01 00 00 00 00 02 7D 04 15 01 00 00 00 00 02 80 04 15 01 00 00 00 00 02 81 04 15 01 00 00 00 00 02 82 13 15 01 00 00 00 00 02 84 31 15 01 00 00 00 00 02 85 00 15 01 00 00 00 00 02 86 00 15 01 00 00 00 00 02 87 00 15 01 00 00 00 00 02 90 13 15 01 00 00 00 00 02 92 31 15 01 00 00 00 00 02 93 00 15 01 00 00 00 00 02 94 00 15 01 00 00 00 00 02 95 00 15 01 00 00 00 00 02 9C F4 15 01 00 00 00 00 02 9D 01 15 01 00 00 00 00 02 A0 0F 15 01 00 00 00 00 02 A2 0F 15 01 00 00 00 00 02 A3 02 15 01 00 00 00 00 02 A4 04 15 01 00 00 00 00 02 A5 04 15 01 00 00 00 00 02 C4 40 15 01 00 00 00 00 02 C6 C0 15 01 00 00 00 00 02 C9 00 15 01 00 00 00 00 02 D9 80 15 01 00 00 00 00 02 E9 02 15 01 00 00 00 00 02 FF 25 15 01 00 00 00 00 02 FB 01 15 01 00 00 00 00 02 19 E4 15 01 00 00 00 00 02 21 40 15 01 00 00 00 00 02 66 D8 15 01 00 00 00 00 02 68 50 15 01 00 00 00 00 02 69 10 15 01 00 00 00 00 02 6B 00 15 01 00 00 00 00 02 6D 0D 15 01 00 00 00 00 02 6E 48 15 01 00 00 00 00 02 72 41 15 01 00 00 00 00 02 73 4A 15 01 00 00 00 00 02 74 D0 15 01 00 00 00 00 02 77 62 15 01 00 00 00 00 02 79 81 15 01 00 00 00 00 02 7D 03 15 01 00 00 00 00 02 7E 15 15 01 00 00 00 00 02 7F 00 15 01 00 00 00 00 02 84 4D 15 01 00 00 00 00 02 CF 80 15 01 00 00 00 00 02 D6 80 15 01 00 00 00 00 02 D7 80 15 01 00 00 00 00 02 EF 20 15 01 00 00 00 00 02 F0 84 15 01 00 00 00 00 02 FF 26 15 01 00 00 00 00 02 FB 01 15 01 00 00 00 00 02 80 05 15 01 00 00 00 00 02 81 0F 15 01 00 00 00 00 02 83 01 15 01 00 00 00 00 02 84 03 15 01 00 00 00 00 02 85 01 15 01 00 00 00 00 02 86 03 15 01 00 00 00 00 02 87 01 15 01 00 00 00 00 02 88 05 15 01 00 00 00 00 02 8A 1A 15 01 00 00 00 00 02 8B 11 15 01 00 00 00 00 02 8C 24 15 01 00 00 00 00 02 8E 42 15 01 00 00 00 00 02 8F 11 15 01 00 00 00 00 02 90 11 15 01 00 00 00 00 02 91 11 15 01 00 00 00 00 02 9A 80 15 01 00 00 00 00 02 9B 04 15 01 00 00 00 00 02 9C 00 15 01 00 00 00 00 02 9D 00 15 01 00 00 00 00 02 9E 00 15 01 00 00 00 00 02 FF 27 15 01 00 00 00 00 02 FB 01 15 01 00 00 00 00 02 01 68 15 01 00 00 00 00 02 20 81 15 01 00 00 00 00 02 21 6A 15 01 00 00 00 00 02 25 81 15 01 00 00 00 00 02 26 94 15 01 00 00 00 00 02 6E 00 15 01 00 00 00 00 02 6F 00 15 01 00 00 00 00 02 70 00 15 01 00 00 00 00 02 71 00 15 01 00 00 00 00 02 72 00 15 01 00 00 00 00 02 75 00 15 01 00 00 00 00 02 76 00 15 01 00 00 00 00 02 77 00 15 01 00 00 00 00 02 7D 09 15 01 00 00 00 00 02 7E 67 15 01 00 00 00 00 02 80 23 15 01 00 00 00 00 02 82 09 15 01 00 00 00 00 02 83 67 15 01 00 00 00 00 02 88 01 15 01 00 00 00 00 02 89 10 15 01 00 00 00 00 02 A5 10 15 01 00 00 00 00 02 A6 23 15 01 00 00 00 00 02 A7 01 15 01 00 00 00 00 02 B6 40 15 01 00 00 00 00 02 FF 2A 15 01 00 00 00 00 02 FB 01 15 01 00 00 00 00 02 00 91 15 01 00 00 00 00 02 03 20 15 01 00 00 00 00 02 07 50 15 01 00 00 00 00 02 0A 70 15 01 00 00 00 00 02 0C 04 15 01 00 00 00 00 02 0D 40 15 01 00 00 00 00 02 0F 01 15 01 00 00 00 00 02 11 E0 15 01 00 00 00 00 02 15 0F 15 01 00 00 00 00 02 16 A4 15 01 00 00 00 00 02 19 0F 15 01 00 00 00 00 02 1A 78 15 01 00 00 00 00 02 1B 23 15 01 00 00 00 00 02 1D 36 15 01 00 00 00 00 02 1E 3E 15 01 00 00 00 00 02 1F 3E 15 01 00 00 00 00 02 20 3E 15 01 00 00 00 00 02 28 FD 15 01 00 00 00 00 02 29 12 15 01 00 00 00 00 02 2A E1 15 01 00 00 00 00 02 2D 0A 15 01 00 00 00 00 02 30 49 15 01 00 00 00 00 02 33 96 15 01 00 00 00 00 02 34 FF 15 01 00 00 00 00 02 35 40 15 01 00 00 00 00 02 36 DE 15 01 00 00 00 00 02 37 F9 15 01 00 00 00 00 02 38 45 15 01 00 00 00 00 02 39 D9 15 01 00 00 00 00 02 3A 49 15 01 00 00 00 00 02 4A F0 15 01 00 00 00 00 02 FF 20 15 01 00 00 00 00 02 FB 01 39 01 00 00 00 00 11 B0 00 00 00 17 00 46 00 63 00 81 00 96 00 AB 00 BD 39 01 00 00 00 00 11 B1 00 CF 01 03 01 2F 01 6E 01 9D 01 E7 02 22 02 24 39 01 00 00 00 00 11 B2 02 5D 02 9B 02 C4 02 F9 03 1B 03 48 03 56 03 65 39 01 00 00 00 00 0F B3 03 75 03 87 03 9B 03 B1 03 CA 03 D7 00 00 39 01 00 00 00 00 11 B4 00 00 00 19 00 4B 00 69 00 87 00 9C 00 B2 00 C3 39 01 00 00 00 00 11 B5 00 D5 01 0B 01 35 01 73 01 A3 01 EC 02 27 02 29 39 01 00 00 00 00 11 B6 02 60 02 9F 02 C7 02 FB 03 1D 03 4C 03 5A 03 69 39 01 00 00 00 00 0F B7 03 7A 03 8C 03 A0 03 B5 03 CB 03 D7 00 00 39 01 00 00 00 00 11 B8 00 00 00 19 00 4D 00 6A 00 87 00 9C 00 B1 00 C2 39 01 00 00 00 00 11 B9 00 D3 01 08 01 32 01 70 01 9F 01 E8 02 23 02 25 39 01 00 00 00 00 11 BA 02 5C 02 9B 02 C3 02 F8 03 1A 03 4C 03 5B 03 6B 39 01 00 00 00 00 0F BB 03 7D 03 92 03 A7 03 BB 03 CE 03 D7 00 00 15 01 00 00 00 00 02 FF 21 15 01 00 00 00 00 02 FB 01 39 01 00 00 00 00 11 B0 00 00 00 17 00 46 00 63 00 81 00 96 00 AB 00 BD 39 01 00 00 00 00 11 B1 00 CF 01 03 01 2F 01 6E 01 9D 01 E7 02 22 02 24 39 01 00 00 00 00 11 B2 02 5D 02 9B 02 C4 02 F9 03 1B 03 48 03 56 03 65 39 01 00 00 00 00 0F B3 03 75 03 87 03 9B 03 B1 03 CA 03 D7 00 00 39 01 00 00 00 00 11 B4 00 00 00 19 00 4B 00 69 00 87 00 9C 00 B2 00 C3 39 01 00 00 00 00 11 B5 00 D5 01 0B 01 35 01 73 01 A3 01 EC 02 27 02 29 39 01 00 00 00 00 11 B6 02 60 02 9F 02 C7 02 FB 03 1D 03 4C 03 5A 03 69 39 01 00 00 00 00 0F B7 03 7A 03 8C 03 A0 03 B5 03 CB 03 D7 00 00 39 01 00 00 00 00 11 B8 00 00 00 19 00 4D 00 6A 00 87 00 9C 00 B1 00 C2 39 01 00 00 00 00 11 B9 00 D3 01 08 01 32 01 70 01 9F 01 E8 02 23 02 25 39 01 00 00 00 00 11 BA 02 5C 02 9B 02 C3 02 F8 03 1A 03 4C 03 5B 03 6B 39 01 00 00 00 00 0F BB 03 7D 03 92 03 A7 03 BB 03 CE 03 D7 00 00 15 01 00 00 00 00 02 FF 10 15 01 00 00 00 00 02 FF F0 15 01 00 00 00 00 02 FB 01 15 01 00 00 00 00 02 5A 00 15 01 00 00 00 00 02 FF 10 15 01 00 00 00 00 02 FF 10 15 01 00 00 00 00 02 FB 01 15 01 00 00 00 00 02 51 FF 15 01 00 00 00 00 02 53 2C 15 01 00 00 00 00 02 55 01 05 01 00 00 C8 00 01 11 05 01 00 00 96 00 01 29];
                    qcom,mdss-dsi-on-command-state = "dsi_lp_mode";
                    qcom,mdss-dsi-panel-framerate = <0x78>;
                    qcom,mdss-dsi-panel-height = <0x968>;
                    qcom,mdss-dsi-panel-phy-timings = [00 1E 08 08 24 22 08 08 08 02 04 00 1B 18];
                    qcom,mdss-dsi-panel-width = <0x438>;
                    qcom,mdss-dsi-v-back-porch = <0xA>;
                    qcom,mdss-dsi-v-front-porch = <0x2E>;
                    qcom,mdss-dsi-v-pulse-width = <0xA>;
                };
            };
        };
        qcom,mdss_dsi_nt36672e_fhd_plus_90hz_video {
            pwms = <&pm6125_pwm 0x0 0x0>;
            qcom,adjust-timer-wakeup-ms = <0x1>;
            qcom,bl-pmic-pwm-period-usecs = <0x64>;
            qcom,dsi-ctrl-num = <0x0>;
            qcom,dsi-phy-num = <0x0>;
            qcom,dsi-select-clocks = "pll_byte_clk0", "pll_dsi_clk0";
            qcom,mdss-dsi-bl-max-level = <0xFFF>;
            qcom,mdss-dsi-bl-min-level = <0x1>;
            qcom,mdss-dsi-bl-pmic-control-type = "bl_ctrl_pwm";
            qcom,mdss-dsi-bllp-eof-power-mode;
            qcom,mdss-dsi-bllp-power-mode;
            qcom,mdss-dsi-border-color = <0x0>;
            qcom,mdss-dsi-bpp = <0x18>;
            qcom,mdss-dsi-dma-trigger = "trigger_sw";
            qcom,mdss-dsi-lane-0-state;
            qcom,mdss-dsi-lane-1-state;
            qcom,mdss-dsi-lane-2-state;
            qcom,mdss-dsi-lane-3-state;
            qcom,mdss-dsi-mdp-trigger = "none";
            qcom,mdss-dsi-panel-blackness-level = <0x1361>;
            qcom,mdss-dsi-panel-hdr-color-primaries = <0x9858 0x3E80 0x83D6 0x9B78 0x33C2 0x8692 0x1D4C 0xBB8>;
            qcom,mdss-dsi-panel-hdr-enabled;
            qcom,mdss-dsi-panel-name = "nt36672e 90Hz fhd plus video mode panel with DSC";
            qcom,mdss-dsi-panel-peak-brightness = <0x626B50>;
            qcom,mdss-dsi-panel-status-check-mode = "reg_read";
            qcom,mdss-dsi-panel-status-command = <0x6010001 0x10A>;
            qcom,mdss-dsi-panel-status-command-state = "dsi_lp_mode";
            qcom,mdss-dsi-panel-status-read-length = <0x1>;
            qcom,mdss-dsi-panel-status-value = <0x9C>;
            qcom,mdss-dsi-panel-type = "dsi_video_mode";
            qcom,mdss-dsi-reset-sequence = <0x1 0xA 0x0 0xA 0x1 0xA>;
            qcom,mdss-dsi-stream = <0x0>;
            qcom,mdss-dsi-traffic-mode = "burst_mode";
            qcom,mdss-dsi-tx-eot-append;
            qcom,mdss-dsi-virtual-channel-id = <0x0>;
            qcom,panel-supply-entries = <&dsi_panel_pwr_supply_no_labibb>;
            qcom,platform-reset-gpio = <&tlmm 0x52 0x0>;
            qcom,mdss-dsi-display-timings {
                timing@0 {
                    cell-index = <0x0>;
                    qcom,compression-mode = "dsc";
                    qcom,default-topology-index = <0x0>;
                    qcom,display-topology = <0x1 0x1 0x1>;
                    qcom,mdss-dsc-bit-per-component = <0x8>;
                    qcom,mdss-dsc-bit-per-pixel = <0x8>;
                    qcom,mdss-dsc-block-prediction-enable;
                    qcom,mdss-dsc-slice-height = <0x8>;
                    qcom,mdss-dsc-slice-per-pkt = <0x1>;
                    qcom,mdss-dsc-slice-width = <0x21C>;
                    qcom,mdss-dsi-h-back-porch = <0x44>;
                    qcom,mdss-dsi-h-front-porch = <0x4C>;
                    qcom,mdss-dsi-h-pulse-width = <0xA>;
                    qcom,mdss-dsi-h-sync-skew = <0x0>;
                    qcom,mdss-dsi-off-command = <0x5010000 0x10000128 0x5010000 0x32000110>;
                    qcom,mdss-dsi-off-command-state = "dsi_lp_mode";
                    qcom,mdss-dsi-on-command = [39 01 00 00 00 00 02 FF 10 39 01 00 00 00 00 02 FB 01 39 01 00 00 00 00 02 B0 00 39 01 00 00 00 00 02 C0 03 39 01 00 00 00 00 11 C1 89 28 00 08 00 AA 02 0E 00 2B 00 07 0D B7 0C B7 39 01 00 00 00 00 03 C2 1B A0 39 01 00 00 00 00 02 FF 20 39 01 00 00 00 00 02 FB 01 39 01 00 00 00 00 02 01 66 39 01 00 00 00 00 02 06 40 39 01 00 00 00 00 02 07 38 39 01 00 00 00 00 02 18 66 39 01 00 00 00 00 02 1B 01 39 01 00 00 00 00 02 5C 90 39 01 00 00 00 00 02 5E AA 39 01 00 00 00 00 02 69 91 39 01 00 00 00 00 02 89 0D 39 01 00 00 00 00 02 8A 0D 39 01 00 00 00 00 02 8D 0D 39 01 00 00 00 00 02 8E 0D 39 01 00 00 00 00 02 8F 0D 39 01 00 00 00 00 02 91 0D 39 01 00 00 00 00 02 95 D1 39 01 00 00 00 00 02 96 D1 39 01 00 00 00 00 02 F2 65 39 01 00 00 00 00 02 F3 64 39 01 00 00 00 00 02 F4 65 39 01 00 00 00 00 02 F5 64 39 01 00 00 00 00 02 F6 65 39 01 00 00 00 00 02 F7 64 39 01 00 00 00 00 02 F8 65 39 01 00 00 00 00 02 F9 64 39 01 00 00 00 00 02 FF 24 39 01 00 00 00 00 02 FB 01 39 01 00 00 00 00 02 01 0F 39 01 00 00 00 00 02 03 0C 39 01 00 00 00 00 02 05 1D 39 01 00 00 00 00 02 08 2F 39 01 00 00 00 00 02 09 2E 39 01 00 00 00 00 02 0A 2D 39 01 00 00 00 00 02 0B 2C 39 01 00 00 00 00 02 11 17 39 01 00 00 00 00 02 12 13 39 01 00 00 00 00 02 13 15 39 01 00 00 00 00 02 15 14 39 01 00 00 00 00 02 16 16 39 01 00 00 00 00 02 17 18 39 01 00 00 00 00 02 1B 01 39 01 00 00 00 00 02 1D 1D 39 01 00 00 00 00 02 20 2F 39 01 00 00 00 00 02 21 2E 39 01 00 00 00 00 02 22 2D 39 01 00 00 00 00 02 23 2C 39 01 00 00 00 00 02 29 17 39 01 00 00 00 00 02 2A 13 39 01 00 00 00 00 02 2B 15 39 01 00 00 00 00 02 2F 14 39 01 00 00 00 00 02 30 16 39 01 00 00 00 00 02 31 18 39 01 00 00 00 00 02 32 04 39 01 00 00 00 00 02 34 10 39 01 00 00 00 00 02 35 1F 39 01 00 00 00 00 02 36 1F 39 01 00 00 00 00 02 4D 19 39 01 00 00 00 00 02 4E 45 39 01 00 00 00 00 02 4F 45 39 01 00 00 00 00 02 53 45 39 01 00 00 00 00 02 71 30 39 01 00 00 00 00 02 79 11 39 01 00 00 00 00 02 7A 82 39 01 00 00 00 00 02 7B 94 39 01 00 00 00 00 02 7D 04 39 01 00 00 00 00 02 80 04 39 01 00 00 00 00 02 81 04 39 01 00 00 00 00 02 82 13 39 01 00 00 00 00 02 84 31 39 01 00 00 00 00 02 85 00 39 01 00 00 00 00 02 86 00 39 01 00 00 00 00 02 87 00 39 01 00 00 00 00 02 90 13 39 01 00 00 00 00 02 92 31 39 01 00 00 00 00 02 93 00 39 01 00 00 00 00 02 94 00 39 01 00 00 00 00 02 95 00 39 01 00 00 00 00 02 9C F4 39 01 00 00 00 00 02 9D 01 39 01 00 00 00 00 02 A0 14 39 01 00 00 00 00 02 A2 14 39 01 00 00 00 00 02 A3 02 39 01 00 00 00 00 02 A4 04 39 01 00 00 00 00 02 A5 04 39 01 00 00 00 00 02 C4 40 39 01 00 00 00 00 02 C6 C0 39 01 00 00 00 00 02 C9 00 39 01 00 00 00 00 02 D9 80 39 01 00 00 00 00 02 E9 02 39 01 00 00 00 00 02 FF 25 39 01 00 00 00 00 02 FB 01 39 01 00 00 00 00 02 0F 1B 39 01 00 00 00 00 02 19 E4 39 01 00 00 00 00 02 21 40 39 01 00 00 00 00 02 66 D8 39 01 00 00 00 00 02 68 50 39 01 00 00 00 00 02 69 10 39 01 00 00 00 00 02 6B 00 39 01 00 00 00 00 02 6D 0D 39 01 00 00 00 00 02 6E 48 39 01 00 00 00 00 02 72 41 39 01 00 00 00 00 02 73 4A 39 01 00 00 00 00 02 74 D0 39 01 00 00 00 00 02 77 62 39 01 00 00 00 00 02 79 7F 39 01 00 00 00 00 02 7D 40 39 01 00 00 00 00 02 7F 00 39 01 00 00 00 00 02 80 04 39 01 00 00 00 00 02 84 0D 39 01 00 00 00 00 02 CF 80 39 01 00 00 00 00 02 D6 80 39 01 00 00 00 00 02 D7 80 39 01 00 00 00 00 02 EF 20 39 01 00 00 00 00 02 F0 84 39 01 00 00 00 00 02 FF 26 39 01 00 00 00 00 02 FB 01 39 01 00 00 00 00 02 15 04 39 01 00 00 00 00 02 81 14 39 01 00 00 00 00 02 83 02 39 01 00 00 00 00 02 84 03 39 01 00 00 00 00 02 85 01 39 01 00 00 00 00 02 86 03 39 01 00 00 00 00 02 87 01 39 01 00 00 00 00 02 88 06 39 01 00 00 00 00 02 8A 1A 39 01 00 00 00 00 02 8B 11 39 01 00 00 00 00 02 8C 24 39 01 00 00 00 00 02 8E 42 39 01 00 00 00 00 02 8F 11 39 01 00 00 00 00 02 90 11 39 01 00 00 00 00 02 91 11 39 01 00 00 00 00 02 9A 81 39 01 00 00 00 00 02 9B 03 39 01 00 00 00 00 02 9C 00 39 01 00 00 00 00 02 9D 00 39 01 00 00 00 00 02 9E 00 39 01 00 00 00 00 02 FF 27 39 01 00 00 00 00 02 FB 01 39 01 00 00 00 00 02 01 68 39 01 00 00 00 00 02 20 81 39 01 00 00 00 00 02 21 EA 39 01 00 00 00 00 02 25 82 39 01 00 00 00 00 02 26 1F 39 01 00 00 00 00 02 6E 00 39 01 00 00 00 00 02 6F 00 39 01 00 00 00 00 02 70 00 39 01 00 00 00 00 02 71 00 39 01 00 00 00 00 02 72 00 39 01 00 00 00 00 02 75 00 39 01 00 00 00 00 02 76 00 39 01 00 00 00 00 02 77 00 39 01 00 00 00 00 02 7D 09 39 01 00 00 00 00 02 7E 67 39 01 00 00 00 00 02 80 23 39 01 00 00 00 00 02 82 09 39 01 00 00 00 00 02 83 67 39 01 00 00 00 00 02 88 01 39 01 00 00 00 00 02 89 10 39 01 00 00 00 00 02 A5 10 39 01 00 00 00 00 02 A6 23 39 01 00 00 00 00 02 A7 01 39 01 00 00 00 00 02 B6 40 39 01 00 00 00 00 02 E3 02 39 01 00 00 00 00 02 E4 E0 39 01 00 00 00 00 02 E5 01 39 01 00 00 00 00 02 E6 70 39 01 00 00 00 00 02 E9 03 39 01 00 00 00 00 02 EA 2F 39 01 00 00 00 00 02 EB 01 39 01 00 00 00 00 02 EC 98 39 01 00 00 00 00 02 FF 2A 39 01 00 00 00 00 02 FB 01 39 01 00 00 00 00 02 00 91 39 01 00 00 00 00 02 03 20 39 01 00 00 00 00 02 07 5A 39 01 00 00 00 00 02 0A 70 39 01 00 00 00 00 02 0D 40 39 01 00 00 00 00 02 0E 02 39 01 00 00 00 00 02 11 F0 39 01 00 00 00 00 02 15 0F 39 01 00 00 00 00 02 16 65 39 01 00 00 00 00 02 19 0F 39 01 00 00 00 00 02 1A 39 39 01 00 00 00 00 02 1B 14 39 01 00 00 00 00 02 1D 36 39 01 00 00 00 00 02 1E 4F 39 01 00 00 00 00 02 1F 4F 39 01 00 00 00 00 02 20 4F 39 01 00 00 00 00 02 28 E4 39 01 00 00 00 00 02 29 17 39 01 00 00 00 00 02 2A F5 39 01 00 00 00 00 02 2D 06 39 01 00 00 00 00 02 2F 04 39 01 00 00 00 00 02 30 54 39 01 00 00 00 00 02 33 04 39 01 00 00 00 00 02 34 E6 39 01 00 00 00 00 02 35 32 39 01 00 00 00 00 02 36 02 39 01 00 00 00 00 02 37 E1 39 01 00 00 00 00 02 38 36 39 01 00 00 00 00 02 39 FE 39 01 00 00 00 00 02 3A 14 39 01 00 00 00 00 02 46 40 39 01 00 00 00 00 02 47 02 39 01 00 00 00 00 02 4A F0 39 01 00 00 00 00 02 4E 0F 39 01 00 00 00 00 02 4F 65 39 01 00 00 00 00 02 52 0F 39 01 00 00 00 00 02 53 39 39 01 00 00 00 00 02 54 14 39 01 00 00 00 00 02 56 36 39 01 00 00 00 00 02 57 7E 39 01 00 00 00 00 02 58 7E 39 01 00 00 00 00 02 59 7E 39 01 00 00 00 00 02 60 80 39 01 00 00 00 00 02 61 C9 39 01 00 00 00 00 02 62 03 39 01 00 00 00 00 02 63 FB 39 01 00 00 00 00 02 64 03 39 01 00 00 00 00 02 65 05 39 01 00 00 00 00 02 66 01 39 01 00 00 00 00 02 67 04 39 01 00 00 00 00 02 68 91 39 01 00 00 00 00 02 6A 19 39 01 00 00 00 00 02 6B CB 39 01 00 00 00 00 02 6C 20 39 01 00 00 00 00 02 6D E5 39 01 00 00 00 00 02 6E C8 39 01 00 00 00 00 02 6F 22 39 01 00 00 00 00 02 70 E3 39 01 00 00 00 00 02 71 04 39 01 00 00 00 00 02 7A 07 39 01 00 00 00 00 02 7B 40 39 01 00 00 00 00 02 7D 01 39 01 00 00 00 00 02 7F 2C 39 01 00 00 00 00 02 83 0F 39 01 00 00 00 00 02 84 65 39 01 00 00 00 00 02 87 0F 39 01 00 00 00 00 02 88 39 39 01 00 00 00 00 02 89 14 39 01 00 00 00 00 02 8B 36 39 01 00 00 00 00 02 8C 39 39 01 00 00 00 00 02 8D 39 39 01 00 00 00 00 02 8E 39 39 01 00 00 00 00 02 95 80 39 01 00 00 00 00 02 96 FD 39 01 00 00 00 00 02 97 14 39 01 00 00 00 00 02 98 B3 39 01 00 00 00 00 02 99 01 39 01 00 00 00 00 02 9A 08 39 01 00 00 00 00 02 9B 02 39 01 00 00 00 00 02 9C 4C 39 01 00 00 00 00 02 9D BC 39 01 00 00 00 00 02 9F AC 39 01 00 00 00 00 02 A0 FF 39 01 00 00 00 00 02 A2 44 39 01 00 00 00 00 02 A3 78 39 01 00 00 00 00 02 A4 F8 39 01 00 00 00 00 02 A5 4A 39 01 00 00 00 00 02 A6 72 39 01 00 00 00 00 02 A7 4C 39 01 00 00 00 00 02 FF 2C 39 01 00 00 00 00 02 FB 01 39 01 00 00 00 00 02 00 02 39 01 00 00 00 00 02 01 02 39 01 00 00 00 00 02 02 02 39 01 00 00 00 00 02 03 16 39 01 00 00 00 00 02 04 16 39 01 00 00 00 00 02 05 16 39 01 00 00 00 00 02 0D 1F 39 01 00 00 00 00 02 0E 1F 39 01 00 00 00 00 02 16 1B 39 01 00 00 00 00 02 17 4B 39 01 00 00 00 00 02 18 4B 39 01 00 00 00 00 02 19 4B 39 01 00 00 00 00 02 2A 03 39 01 00 00 00 00 02 4D 16 39 01 00 00 00 00 02 4E 02 39 01 00 00 00 00 02 4F 2F 39 01 00 00 00 00 02 53 02 39 01 00 00 00 00 02 54 02 39 01 00 00 00 00 02 55 02 39 01 00 00 00 00 02 56 0E 39 01 00 00 00 00 02 58 0E 39 01 00 00 00 00 02 59 0E 39 01 00 00 00 00 02 61 1F 39 01 00 00 00 00 02 62 1F 39 01 00 00 00 00 02 6A 14 39 01 00 00 00 00 02 6B 34 39 01 00 00 00 00 02 6C 34 39 01 00 00 00 00 02 6D 34 39 01 00 00 00 00 02 7E 03 39 01 00 00 00 00 02 9D 0E 39 01 00 00 00 00 02 9E 02 39 01 00 00 00 00 02 9F 02 39 01 00 00 00 00 02 FF 20 39 01 00 00 00 00 02 FB 01 39 01 00 00 00 00 11 B0 00 00 00 15 00 3F 00 5F 00 7E 00 97 00 AF 00 C3 39 01 00 00 00 00 11 B1 00 D7 01 0A 01 32 01 6F 01 9E 01 E5 02 1D 02 1E 39 01 00 00 00 00 11 B2 02 56 02 94 02 BC 02 F1 03 13 03 41 03 4F 03 5F 39 01 00 00 00 00 0F B3 03 71 03 84 03 99 03 B0 03 CA 03 D7 00 00 39 01 00 00 00 00 11 B4 00 00 00 17 00 46 00 69 00 8C 00 A5 00 BE 00 D1 39 01 00 00 00 00 11 B5 00 E4 01 18 01 40 01 7C 01 AA 01 F0 02 27 02 28 39 01 00 00 00 00 11 B6 02 5E 02 9B 02 C3 02 F6 03 18 03 45 03 54 03 63 39 01 00 00 00 00 0F B7 03 75 03 87 03 9C 03 B2 03 CA 03 D7 00 00 39 01 00 00 00 00 11 B8 00 00 00 18 00 49 00 6B 00 8E 00 A8 00 C1 00 D3 39 01 00 00 00 00 11 B9 00 E5 01 18 01 3F 01 7B 01 A8 01 EC 02 24 02 26 39 01 00 00 00 00 11 BA 02 5A 02 97 02 C0 02 F4 03 15 03 43 03 51 03 61 39 01 00 00 00 00 0F BB 03 72 03 85 03 9A 03 B1 03 CA 03 D7 00 00 39 01 00 00 00 00 02 C6 00 39 01 00 00 00 00 02 C7 00 39 01 00 00 00 00 02 C8 00 39 01 00 00 00 00 02 C9 00 39 01 00 00 00 00 02 CA 00 39 01 00 00 00 00 02 CB 00 39 01 00 00 00 00 02 CC 00 39 01 00 00 00 00 02 CD 00 39 01 00 00 00 00 02 CE 00 39 01 00 00 00 00 02 CF 00 39 01 00 00 00 00 02 D0 00 39 01 00 00 00 00 02 D1 00 39 01 00 00 00 00 02 D2 00 39 01 00 00 00 00 02 D3 00 39 01 00 00 00 00 02 D4 00 39 01 00 00 00 00 02 D5 00 39 01 00 00 00 00 02 D6 00 39 01 00 00 00 00 02 D7 00 39 01 00 00 00 00 02 D8 00 39 01 00 00 00 00 02 D9 00 39 01 00 00 00 00 02 DA 00 39 01 00 00 00 00 02 DB 00 39 01 00 00 00 00 02 DC 00 39 01 00 00 00 00 02 DD 00 39 01 00 00 00 00 02 DE 00 39 01 00 00 00 00 02 DF 00 39 01 00 00 00 00 02 E0 00 39 01 00 00 00 00 02 E1 00 39 01 00 00 00 00 02 E2 00 39 01 00 00 00 00 02 E3 00 39 01 00 00 00 00 02 E4 00 39 01 00 00 00 00 02 E5 00 39 01 00 00 00 00 02 E6 00 39 01 00 00 00 00 02 E7 00 39 01 00 00 00 00 02 E8 00 39 01 00 00 00 00 02 E9 00 39 01 00 00 00 00 02 FF 21 39 01 00 00 00 00 02 FB 01 39 01 00 00 00 00 11 B0 00 00 00 15 00 3F 00 5F 00 7E 00 97 00 AF 00 C3 39 01 00 00 00 00 11 B1 00 D7 01 0A 01 32 01 6F 01 9E 01 E5 02 1D 02 1E 39 01 00 00 00 00 11 B2 02 56 02 94 02 BC 02 F1 03 13 03 41 03 4F 03 5F 39 01 00 00 00 00 0F B3 03 71 03 84 03 99 03 B0 03 CA 03 D7 00 00 39 01 00 00 00 00 11 B4 00 00 00 17 00 46 00 69 00 8C 00 A5 00 BE 00 D1 39 01 00 00 00 00 11 B5 00 E4 01 18 01 40 01 7C 01 AA 01 F0 02 27 02 28 39 01 00 00 00 00 11 B6 02 5E 02 9B 02 C3 02 F6 03 18 03 45 03 54 03 63 39 01 00 00 00 00 0F B7 03 75 03 87 03 9C 03 B2 03 CA 03 D7 00 00 39 01 00 00 00 00 11 B8 00 00 00 18 00 49 00 6B 00 8E 00 A8 00 C1 00 D3 39 01 00 00 00 00 11 B9 00 E5 01 18 01 3F 01 7B 01 A8 01 EC 02 24 02 26 39 01 00 00 00 00 11 BA 02 5A 02 97 02 C0 02 F4 03 15 03 43 03 51 03 61 39 01 00 00 00 00 0F BB 03 72 03 85 03 9A 03 B1 03 CA 03 D7 00 00 39 01 00 00 00 00 02 FF E0 39 01 00 00 00 00 02 FB 01 39 01 00 00 00 00 02 35 82 39 01 00 00 00 00 02 85 32 39 01 00 00 00 00 02 FF F0 39 01 00 00 00 00 02 FB 01 39 01 00 00 00 00 02 1C 01 39 01 00 00 00 00 02 33 01 39 01 00 00 00 00 02 5A 00 39 01 00 00 00 00 02 FF D0 39 01 00 00 00 00 02 FB 01 39 01 00 00 00 00 02 53 22 39 01 00 00 00 00 02 54 02 39 01 00 00 00 00 02 FF C0 39 01 00 00 00 00 02 FB 01 39 01 00 00 00 00 02 9C 11 39 01 00 00 00 00 02 9D 11 39 01 00 00 00 00 02 FF 2B 39 01 00 00 00 00 02 FB 01 39 01 00 00 00 00 02 B7 0A 39 01 00 00 00 00 02 B8 1C 39 01 00 00 00 00 02 C0 01 39 01 00 00 00 00 02 FF 10 39 01 00 00 00 00 02 35 01 39 01 00 00 00 00 02 51 FF 39 01 00 00 00 00 02 53 0C 39 01 00 00 00 00 02 55 00 05 01 00 00 78 00 01 11 05 01 00 00 28 00 01 29];
                    qcom,mdss-dsi-on-command-state = "dsi_lp_mode";
                    qcom,mdss-dsi-panel-framerate = <0x5A>;
                    qcom,mdss-dsi-panel-height = <0x968>;
                    qcom,mdss-dsi-panel-phy-timings = [00 18 06 06 21 20 06 06 07 02 04 00 16 16];
                    qcom,mdss-dsi-panel-width = <0x438>;
                    qcom,mdss-dsi-v-back-porch = <0xA>;
                    qcom,mdss-dsi-v-front-porch = <0x2E>;
                    qcom,mdss-dsi-v-pulse-width = <0xA>;
                };
            };
        };
        qcom,mdss_dsi_panel_m7_38_0c_0a_fhdp_video {
            qcom,bl-update-flag = "delay_until_first_frame";
            qcom,dsi-ctrl-num = <0x0>;
            qcom,dsi-phy-num = <0x0>;
            qcom,dsi-select-clocks = "pll_byte_clk0", "pll_dsi_clk0";
            qcom,dsi-supported-dfps-list = <0x78 0x5A 0x3C>;
            qcom,esd-err-irq-gpio = <&tlmm 0x21 0x2002>;
            qcom,mdss-brightness-init-level = <0x133>;
            qcom,mdss-brightness-max-level = <0x7FF>;
            qcom,mdss-dsi-bl-dcs-type-ss-ea;
            qcom,mdss-dsi-bl-inverted-dbv;
            qcom,mdss-dsi-bl-max-level = <0x7FF>;
            qcom,mdss-dsi-bl-min-level = <0x1>;
            qcom,mdss-dsi-bl-move-high-8b;
            qcom,mdss-dsi-bl-pmic-control-type = "bl_ctrl_dcs";
            qcom,mdss-dsi-bllp-eof-power-mode;
            qcom,mdss-dsi-bllp-power-mode;
            qcom,mdss-dsi-border-color = <0x0>;
            qcom,mdss-dsi-bpp = <0x18>;
            qcom,mdss-dsi-color-order = "rgb_swap_rgb";
            qcom,mdss-dsi-dma-trigger = "trigger_sw";
            qcom,mdss-dsi-lane-0-state;
            qcom,mdss-dsi-lane-1-state;
            qcom,mdss-dsi-lane-2-state;
            qcom,mdss-dsi-lane-3-state;
            qcom,mdss-dsi-lp11-init;
            qcom,mdss-dsi-mdp-trigger = "none";
            qcom,mdss-dsi-oled-panel-video-mode;
            qcom,mdss-dsi-pan-enable-dynamic-fps;
            qcom,mdss-dsi-pan-fps-update = "dfps_immediate_porch_mode_vfp";
            qcom,mdss-dsi-panel-id = <0x0>;
            qcom,mdss-dsi-panel-name = "m7 38 0c 0a video mode fhdp dsi panel";
            qcom,mdss-dsi-panel-type = "dsi_video_mode";
            qcom,mdss-dsi-reset-sequence = <0x0 0xA 0x1 0xA>;
            qcom,mdss-dsi-stream = <0x0>;
            qcom,mdss-dsi-traffic-mode = "burst_mode";
            qcom,mdss-dsi-tx-eot-append;
            qcom,mdss-dsi-underflow-color = <0xFF>;
            qcom,mdss-dsi-virtual-channel-id = <0x0>;
            qcom,mdss-pan-physical-height-dimension = <0x60A>;
            qcom,mdss-pan-physical-width-dimension = <0x2B7>;
            qcom,panel-supply-entries = <&dsi_panel_pwr_supply_no_labibb>;
            qcom,platform-en-gpio = <&pm6125_gpios 0x9 0x0>;
            qcom,platform-reset-gpio = <&tlmm 0x52 0x0>;
            qcom,mdss-dsi-display-timings {
                timing@0 {
                    mi,mdss-dsi-dispparam-dimming-hbmoff-command = [39 01 00 00 00 00 03 F0 5A 5A 39 01 00 00 00 00 04 B0 00 0D B2 39 01 00 00 00 00 02 B2 05 39 01 00 00 00 00 04 B0 00 0C B2 39 01 00 00 00 00 02 B2 30 39 01 00 00 00 00 02 F7 0B 39 01 00 00 00 00 03 F0 A5 A5];
                    mi,mdss-dsi-dispparam-dimming-hbmoff-command-state = "dsi_hs_mode";
                    mi,mdss-dsi-dispparam-dimming-hbmon-command = [39 01 00 00 00 00 03 F0 5A 5A 39 01 00 00 00 00 04 B0 00 0D B2 39 01 00 00 00 00 02 B2 30 39 01 00 00 00 00 04 B0 00 0C B2 39 01 00 00 00 00 02 B2 30 39 01 00 00 00 00 02 F7 0B 39 01 00 00 00 00 03 F0 A5 A5];
                    mi,mdss-dsi-dispparam-dimming-hbmon-command-state = "dsi_hs_mode";
                    mi,mdss-dsi-doze-hbm-command = [39 01 00 00 00 00 03 51 01 1B];
                    mi,mdss-dsi-doze-hbm-command-state = "dsi_hs_mode";
                    mi,mdss-dsi-doze-lbm-command = [39 01 00 00 00 00 03 51 00 18];
                    mi,mdss-dsi-doze-lbm-command-state = "dsi_hs_mode";
                    mi,mdss-dsi-flat-mode-off-command = <0x39010040 0x3F0 0x5A5A3901 0x400000 0x4B00089 0xB1390100 0x40000002 0xB10D3901 0x400000 0x4B00003 0xB8390100 0x40000005 0xB8FF8F01 0xFF390100 0x40000004 0xB000F8B5 0x39010040 0xFB5 0x82171717 0x86FB0A80 0x0 0xFF903901 0x0 0x3F0A5A5>;
                    mi,mdss-dsi-flat-mode-off-command-state = "dsi_hs_mode";
                    mi,mdss-dsi-flat-mode-on-command = <0x39010040 0x3F0 0x5A5A3901 0x400000 0x4B00089 0xB1390100 0x40000002 0xB12D3901 0x400000 0x4B00003 0xB8390100 0x40000005 0xB8FF8F01 0xFF390100 0x40000004 0xB000F8B5 0x39010040 0xFB5 0x82171717 0x86FB0A80 0x0 0xFF903901 0x0 0x3F0A5A5>;
                    mi,mdss-dsi-flat-mode-on-command-state = "dsi_hs_mode";
                    mi,mdss-dsi-hbm-off-command = [39 00 00 40 00 00 02 53 28 39 00 00 00 00 00 03 51 07 FF];
                    mi,mdss-dsi-hbm-off-command-state = "dsi_lp_mode";
                    mi,mdss-dsi-hbm-on-command = <0x39000040 0x253 0xE8390000 0x40000003 0x5107FF39 0x0 0x2F70B>;
                    mi,mdss-dsi-hbm-on-command-state = "dsi_lp_mode";
                    qcom,compression-mode = "dsc";
                    qcom,default-topology-index = <0x0>;
                    qcom,display-topology = <0x1 0x1 0x1>;
                    qcom,mdss-dsc-bit-per-component = <0x8>;
                    qcom,mdss-dsc-bit-per-pixel = <0x8>;
                    qcom,mdss-dsc-block-prediction-enable;
                    qcom,mdss-dsc-scr-version = <0x0>;
                    qcom,mdss-dsc-slice-height = <0x14>;
                    qcom,mdss-dsc-slice-per-pkt = <0x2>;
                    qcom,mdss-dsc-slice-width = <0x21C>;
                    qcom,mdss-dsc-version = <0x11>;
                    qcom,mdss-dsi-dispparam-fps-120hz-command = <0x39000040 0x3F0 0x5A5A3900 0x400000 0x2600139 0x0 0x2F70B>;
                    qcom,mdss-dsi-dispparam-fps-120hz-command-state = "dsi_hs_mode";
                    qcom,mdss-dsi-dispparam-fps-60hz-command = <0x39000040 0x3F0 0x5A5A3900 0x400000 0x2602139 0x0 0x2F70B>;
                    qcom,mdss-dsi-dispparam-fps-60hz-command-state = "dsi_hs_mode";
                    qcom,mdss-dsi-dispparam-fps-90hz-command = <0x39000040 0x3F0 0x5A5A3900 0x400000 0x2600139 0x0 0x2F70B>;
                    qcom,mdss-dsi-dispparam-fps-90hz-command-state = "dsi_hs_mode";
                    qcom,mdss-dsi-h-back-porch = <0x78>;
                    qcom,mdss-dsi-h-front-porch = <0x78>;
                    qcom,mdss-dsi-h-pulse-width = <0x1C>;
                    qcom,mdss-dsi-h-sync-skew = <0x0>;
                    qcom,mdss-dsi-on-command = [39 01 00 00 00 00 03 F0 5A 5A 39 01 00 00 00 00 03 F1 5A 5A 39 01 00 00 00 00 02 D0 08 39 01 00 00 00 00 04 B0 00 25 F2 39 01 00 00 00 00 02 F2 50 39 01 00 00 00 00 04 B0 00 2F F2 39 01 00 00 00 00 02 F2 27 39 01 00 00 00 00 03 F0 A5 A5 39 01 00 00 00 00 03 F1 A5 A5 05 01 00 00 20 00 02 11 00 39 01 00 00 00 00 03 F0 5A 5A 39 01 00 00 00 00 03 B2 01 31 39 01 00 00 00 00 08 DF 09 30 95 43 A9 43 A9 39 01 00 00 00 00 03 F0 A5 A5 39 01 00 00 00 00 02 9D 01 39 01 00 00 00 00 5A 9E 11 00 00 89 30 80 09 60 04 38 00 28 02 1C 02 1C 02 00 02 0E 00 20 03 DD 00 07 00 0C 02 77 02 8B 18 00 10 F0 03 0C 20 00 06 0B 0B 33 0E 1C 2A 38 46 54 62 69 70 77 79 7B 7D 7E 01 02 01 00 09 40 09 BE 19 FC 19 FA 19 F8 1A 38 1A 78 1A B6 2A F6 2B 34 2B 74 3B 74 6B F4 00 39 01 00 00 00 00 03 F0 5A 5A 39 01 00 00 00 00 02 60 01 39 01 00 00 00 00 02 F7 0B 39 01 00 00 00 00 03 F0 A5 A5 39 01 00 00 00 00 03 F0 5A 5A 39 01 00 00 00 00 04 B0 00 40 F2 39 01 00 00 00 00 02 F2 03 39 01 00 00 00 00 03 F0 A5 A5 39 01 00 00 00 00 03 FC 5A 5A 39 00 00 00 00 00 04 B0 00 11 FE 39 00 00 00 00 00 02 FE 00 39 01 00 00 00 00 03 FC A5 A5 39 01 00 00 00 00 04 B0 00 0D B2 39 01 00 00 00 00 02 B2 05 39 01 00 00 00 00 04 B0 00 0C B2 39 01 00 00 00 00 02 B2 30 39 01 00 00 00 00 02 F7 0B 39 01 00 00 00 00 03 F0 A5 A5 39 01 00 00 00 00 03 F0 5A 5A 39 01 00 00 00 00 03 FC 5A 5A 39 01 00 00 00 00 04 ED 01 CD 00 39 01 00 00 00 00 02 E1 93 39 01 00 00 00 00 04 B0 00 06 F4 39 01 00 00 00 00 02 F4 1F 39 01 00 00 00 00 03 F0 A5 A5 39 01 00 00 00 00 03 FC A5 A5 39 01 00 00 00 00 02 53 28 39 01 00 00 64 00 03 51 00 00 05 01 00 00 00 00 02 29 00];
                    qcom,mdss-dsi-on-command-state = "dsi_lp_mode";
                    qcom,mdss-dsi-panel-framerate = <0x78>;
                    qcom,mdss-dsi-panel-height = <0x960>;
                    qcom,mdss-dsi-panel-phy-timings = [00 24 0A 0A 1A 19 09 0A 09 02 04 00 1E 0F];
                    qcom,mdss-dsi-panel-width = <0x438>;
                    qcom,mdss-dsi-pre-off-command = [05 01 00 00 14 00 02 28 00 05 01 00 00 96 00 02 10 00];
                    qcom,mdss-dsi-pre-off-command-state = "dsi_hs_mode";
                    qcom,mdss-dsi-v-back-porch = <0xA>;
                    qcom,mdss-dsi-v-front-porch = <0x14>;
                    qcom,mdss-dsi-v-pulse-width = <0x2>;
                    qcom,mdss-dsi-video-mode;
                };
            };
        };
        qcom,mdss_dsi_panel_m7_38_0c_0b_fhdp_video {
            qcom,bl-update-flag = "delay_until_first_frame";
            qcom,dsi-ctrl-num = <0x0>;
            qcom,dsi-phy-num = <0x0>;
            qcom,dsi-select-clocks = "pll_byte_clk0", "pll_dsi_clk0";
            qcom,dsi-supported-dfps-list = <0x78 0x5A 0x3C>;
            qcom,esd-err-irq-gpio = <&tlmm 0x21 0x2002>;
            qcom,mdss-brightness-init-level = <0x133>;
            qcom,mdss-dsi-bl-dcs-type-ss-ea;
            qcom,mdss-dsi-bl-inverted-dbv;
            qcom,mdss-dsi-bl-max-level = <0x7FF>;
            qcom,mdss-dsi-bl-min-level = <0x1>;
            qcom,mdss-dsi-bl-pmic-control-type = "bl_ctrl_dcs";
            qcom,mdss-dsi-bllp-eof-power-mode;
            qcom,mdss-dsi-bllp-power-mode;
            qcom,mdss-dsi-border-color = <0x0>;
            qcom,mdss-dsi-bpp = <0x18>;
            qcom,mdss-dsi-color-order = "rgb_swap_rgb";
            qcom,mdss-dsi-dma-trigger = "trigger_sw";
            qcom,mdss-dsi-lane-0-state;
            qcom,mdss-dsi-lane-1-state;
            qcom,mdss-dsi-lane-2-state;
            qcom,mdss-dsi-lane-3-state;
            qcom,mdss-dsi-lp11-init;
            qcom,mdss-dsi-mdp-trigger = "none";
            qcom,mdss-dsi-oled-panel-video-mode;
            qcom,mdss-dsi-pan-enable-dynamic-fps;
            qcom,mdss-dsi-pan-fps-update = "dfps_immediate_porch_mode_vfp";
            qcom,mdss-dsi-panel-id = <0x0>;
            qcom,mdss-dsi-panel-name = "m7 38 0c 0b video mode fhdp dsi panel";
            qcom,mdss-dsi-panel-type = "dsi_video_mode";
            qcom,mdss-dsi-reset-sequence = <0x0 0xA 0x1 0xA>;
            qcom,mdss-dsi-stream = <0x0>;
            qcom,mdss-dsi-traffic-mode = "burst_mode";
            qcom,mdss-dsi-tx-eot-append;
            qcom,mdss-dsi-underflow-color = <0xFF>;
            qcom,mdss-dsi-virtual-channel-id = <0x0>;
            qcom,mdss-pan-physical-height-dimension = <0x60A>;
            qcom,mdss-pan-physical-width-dimension = <0x2B7>;
            qcom,panel-supply-entries = <&dsi_panel_pwr_supply_no_labibb>;
            qcom,platform-en-gpio = <&pm6125_gpios 0x9 0x0>;
            qcom,platform-reset-gpio = <&tlmm 0x52 0x0>;
            qcom,mdss-dsi-display-timings {
                timing@0 {
                    mi,mdss-dsi-dispparam-dimming-hbmon-command-state = "dsi_hs_mode";
                    mi,mdss-dsi-doze-hbm-command = [39 01 00 00 00 00 03 51 01 1B];
                    mi,mdss-dsi-doze-hbm-command-state = "dsi_hs_mode";
                    mi,mdss-dsi-doze-lbm-command = [39 01 00 00 00 00 03 51 00 18];
                    mi,mdss-dsi-doze-lbm-command-state = "dsi_hs_mode";
                    mi,mdss-dsi-flat-mode-off-command = <0x39010040 0x3F1 0x5A5A3901 0x400000 0x5B00088 0xB1013901 0x400000 0x29B1270D 0xFE0F9980 0x1FF128F 0xFF12FF38 0x395B0B0B 0xB2E2E2E 0x3E3E3E4A 0x4A4A4E4E 0x4E1B2FDA 0x18748000 0x223901 0x0 0x3F1A5A5>;
                    mi,mdss-dsi-flat-mode-off-command-state = "dsi_hs_mode";
                    mi,mdss-dsi-flat-mode-on-command = [39 01 00 40 00 00 03 F1 5A 5A 39 01 00 40 00 00 05 B0 00 88 B1 01 39 01 00 40 00 00 29 B1 27 2D C5 0F 61 80 01 FF 12 26 FF 12 FF 42 44 6E 0B 0B 0B 2D 2D 2D 3C 3C 3C 47 47 47 4B 4B 4B 1B 2F DA 18 64 80 00 00 22 39 01 00 40 00 00 05 B0 00 03 B8 01 39 01 00 40 00 00 05 B8 FF 8F 01 FF 39 01 00 40 00 00 05 B0 00 F8 B5 01 39 01 00 40 00 00 0F B5 E2 0E 0E 0E 82 1E 95 80 00 00 00 00 FF 90 39 01 00 00 00 00 03 F1 A5 A5];
                    mi,mdss-dsi-flat-mode-on-command-state = "dsi_hs_mode";
                    mi,mdss-dsi-hbm-off-command = [39 00 00 40 00 00 02 53 30 39 00 00 00 00 00 02 F7 07];
                    mi,mdss-dsi-hbm-off-command-state = "dsi_lp_mode";
                    mi,mdss-dsi-hbm-on-command = <0x39000040 0x253 0xF0390000 0x40000003 0x5107FF39 0x0 0x2F707>;
                    mi,mdss-dsi-hbm-on-command-state = "dsi_lp_mode";
                    qcom,compression-mode = "dsc";
                    qcom,default-topology-index = <0x0>;
                    qcom,display-topology = <0x1 0x1 0x1>;
                    qcom,mdss-dsc-bit-per-component = <0x8>;
                    qcom,mdss-dsc-bit-per-pixel = <0x8>;
                    qcom,mdss-dsc-block-prediction-enable;
                    qcom,mdss-dsc-scr-version = <0x0>;
                    qcom,mdss-dsc-slice-height = <0x14>;
                    qcom,mdss-dsc-slice-per-pkt = <0x2>;
                    qcom,mdss-dsc-slice-width = <0x21C>;
                    qcom,mdss-dsc-version = <0x11>;
                    qcom,mdss-dsi-dispparam-fps-120hz-command = <0x39000040 0x3F1 0x5A5A3900 0x400000 0x2600139 0x0 0x2F707>;
                    qcom,mdss-dsi-dispparam-fps-120hz-command-state = "dsi_hs_mode";
                    qcom,mdss-dsi-dispparam-fps-60hz-command = <0x39000040 0x3F1 0x5A5A3900 0x400000 0x2602139 0x0 0x2F707>;
                    qcom,mdss-dsi-dispparam-fps-60hz-command-state = "dsi_hs_mode";
                    qcom,mdss-dsi-dispparam-fps-90hz-command = <0x39000040 0x3F0 0x5A5A3900 0x400000 0x2600139 0x0 0x2F70B>;
                    qcom,mdss-dsi-dispparam-fps-90hz-command-state = "dsi_hs_mode";
                    qcom,mdss-dsi-h-back-porch = <0x78>;
                    qcom,mdss-dsi-h-front-porch = <0x78>;
                    qcom,mdss-dsi-h-pulse-width = <0x1C>;
                    qcom,mdss-dsi-h-sync-skew = <0x0>;
                    qcom,mdss-dsi-off-command = <0x5010000 0xB000128 0x5010000 0x97000110>;
                    qcom,mdss-dsi-off-command-state = "dsi_hs_mode";
                    qcom,mdss-dsi-on-command = [39 01 00 00 00 00 03 F0 5A 5A 39 01 00 00 00 00 03 F1 5A 5A 39 01 00 00 00 00 02 D0 08 39 01 00 00 00 00 04 B0 00 25 F2 39 01 00 00 00 00 02 F2 50 39 01 00 00 00 00 04 B0 00 2F F2 39 01 00 00 00 00 02 F2 27 39 01 00 00 00 00 03 F0 A5 A5 39 01 00 00 00 00 03 F1 A5 A5 05 01 00 00 20 00 02 11 00 39 01 00 00 00 00 03 F0 5A 5A 39 01 00 00 00 00 03 B2 01 31 39 01 00 00 00 00 08 DF 09 30 95 43 A9 43 A9 39 01 00 00 00 00 03 F0 A5 A5 39 01 00 00 00 00 02 9D 01 39 01 00 00 00 00 5A 9E 11 00 00 89 30 80 09 60 04 38 00 28 02 1C 02 1C 02 00 02 0E 00 20 03 DD 00 07 00 0C 02 77 02 8B 18 00 10 F0 03 0C 20 00 06 0B 0B 33 0E 1C 2A 38 46 54 62 69 70 77 79 7B 7D 7E 01 02 01 00 09 40 09 BE 19 FC 19 FA 19 F8 1A 38 1A 78 1A B6 2A F6 2B 34 2B 74 3B 74 6B F4 00 39 01 00 00 00 00 03 F0 5A 5A 39 01 00 00 00 00 02 60 01 39 01 00 00 00 00 02 F7 0B 39 01 00 00 00 00 03 F0 A5 A5 39 01 00 00 00 00 03 F0 5A 5A 39 01 00 00 00 00 04 B0 00 40 F2 39 01 00 00 00 00 02 F2 03 39 01 00 00 00 00 03 F0 A5 A5 39 01 00 00 00 00 03 FC 5A 5A 39 00 00 00 00 00 04 B0 00 11 FE 39 00 00 00 00 00 02 FE 00 39 01 00 00 00 00 03 FC A5 A5 39 01 00 00 00 00 04 B0 00 0D B2 39 01 00 00 00 00 02 B2 05 39 01 00 00 00 00 04 B0 00 0C B2 39 01 00 00 00 00 02 B2 30 39 01 00 00 00 00 02 F7 0B 39 01 00 00 00 00 03 F0 A5 A5 39 01 00 00 00 00 03 F0 5A 5A 39 01 00 00 00 00 03 FC 5A 5A 39 01 00 00 00 00 04 ED 01 CD 00 39 01 00 00 00 00 02 E1 93 39 01 00 00 00 00 04 B0 00 06 F4 39 01 00 00 00 00 02 F4 1F 39 01 00 00 00 00 03 F0 A5 A5 39 01 00 00 00 00 03 FC A5 A5 39 01 00 00 00 00 02 53 28 39 01 00 00 64 00 03 51 00 00 05 01 00 00 00 00 02 29 00];
                    qcom,mdss-dsi-on-command-state = "dsi_lp_mode";
                    qcom,mdss-dsi-panel-framerate = <0x78>;
                    qcom,mdss-dsi-panel-height = <0x960>;
                    qcom,mdss-dsi-panel-phy-timings = [00 24 0A 0A 1A 19 09 0A 09 02 04 00 1E 0F];
                    qcom,mdss-dsi-panel-width = <0x438>;
                    qcom,mdss-dsi-v-back-porch = <0xA>;
                    qcom,mdss-dsi-v-front-porch = <0x14>;
                    qcom,mdss-dsi-v-pulse-width = <0x2>;
                    qcom,mdss-dsi-video-mode;
                };
            };
        };
        qcom,mdss_dsi_sim_video {
            qcom,dsi-ctrl-num = <0x0>;
            qcom,dsi-phy-num = <0x0>;
            qcom,dsi-select-clocks = "pll_byte_clk0", "pll_dsi_clk0";
            qcom,mdss-dsi-bl-pmic-control-type = "bl_ctrl_dcs";
            qcom,mdss-dsi-bllp-eof-power-mode;
            qcom,mdss-dsi-bllp-power-mode;
            qcom,mdss-dsi-border-color = <0x0>;
            qcom,mdss-dsi-bpp = <0x18>;
            qcom,mdss-dsi-dma-trigger = "trigger_sw";
            qcom,mdss-dsi-lane-0-state;
            qcom,mdss-dsi-lane-1-state;
            qcom,mdss-dsi-lane-2-state;
            qcom,mdss-dsi-lane-3-state;
            qcom,mdss-dsi-mdp-trigger = "none";
            qcom,mdss-dsi-panel-blackness-level = <0xC9E>;
            qcom,mdss-dsi-panel-hdr-color-primaries = <0x38A4 0x3C8C 0x7D00 0x4268 0x3C8C 0x7530 0x1F40 0xBB8>;
            qcom,mdss-dsi-panel-hdr-enabled;
            qcom,mdss-dsi-panel-name = "Simulator video mode dsi panel";
            qcom,mdss-dsi-panel-peak-brightness = <0x401640>;
            qcom,mdss-dsi-panel-type = "dsi_video_mode";
            qcom,mdss-dsi-reset-sequence = <0x1 0x0 0x0 0x0 0x1 0x0>;
            qcom,mdss-dsi-stream = <0x0>;
            qcom,mdss-dsi-t-clk-post = <0x4>;
            qcom,mdss-dsi-t-clk-pre = <0x1B>;
            qcom,mdss-dsi-traffic-mode = "non_burst_sync_event";
            qcom,mdss-dsi-underflow-color = <0xFF>;
            qcom,mdss-dsi-virtual-channel-id = <0x0>;
            qcom,panel-ack-disabled;
            qcom,panel-supply-entries = <&dsi_panel_pwr_supply_no_labibb>;
            qcom,platform-reset-gpio = <&tlmm 0x52 0x0>;
            qcom,mdss-dsi-display-timings {
                timing@0 {
                    qcom,default-topology-index = <0x0>;
                    qcom,display-topology = <0x1 0x0 0x1>;
                    qcom,mdss-dsi-h-back-porch = <0x8>;
                    qcom,mdss-dsi-h-front-porch = <0x8>;
                    qcom,mdss-dsi-h-left-border = <0x0>;
                    qcom,mdss-dsi-h-pulse-width = <0x8>;
                    qcom,mdss-dsi-h-right-border = <0x0>;
                    qcom,mdss-dsi-h-sync-pulse = <0x0>;
                    qcom,mdss-dsi-h-sync-skew = <0x0>;
                    qcom,mdss-dsi-off-command = [22 01 00 00 00 00 02 00 00];
                    qcom,mdss-dsi-off-command-state = "dsi_lp_mode";
                    qcom,mdss-dsi-on-command = [32 01 00 00 00 00 02 00 00];
                    qcom,mdss-dsi-on-command-state = "dsi_lp_mode";
                    qcom,mdss-dsi-panel-framerate = <0x3C>;
                    qcom,mdss-dsi-panel-height = <0x1E0>;
                    qcom,mdss-dsi-panel-phy-timings = [01 09 01 01 1B 1B 01 01 02 02 04 00 0A 11];
                    qcom,mdss-dsi-panel-timings = <0x0 0x0 0x0>;
                    qcom,mdss-dsi-panel-width = <0x280>;
                    qcom,mdss-dsi-v-back-porch = <0x6>;
                    qcom,mdss-dsi-v-bottom-border = <0x0>;
                    qcom,mdss-dsi-v-front-porch = <0x6>;
                    qcom,mdss-dsi-v-pulse-width = <0x2>;
                    qcom,mdss-dsi-v-top-border = <0x0>;
                };
            };
        };
        qcom,mdss_dsi_td4330_truly_v2_cmd {
            pwms = <&pm6125_pwm 0x0 0x0>;
            qcom,bl-pmic-pwm-period-usecs = <0x64>;
            qcom,dsi-ctrl-num = <0x0>;
            qcom,dsi-dyn-clk-enable;
            qcom,dsi-dyn-clk-list = <0x38491AB0 0x3758F3D0 0x3794FD88 0x37D10740 0x380D10F0>;
            qcom,dsi-phy-num = <0x0>;
            qcom,dsi-select-clocks = "pll_byte_clk0", "pll_dsi_clk0";
            qcom,mdss-dsi-bl-max-level = <0xFFF>;
            qcom,mdss-dsi-bl-min-level = <0x1>;
            qcom,mdss-dsi-bl-pmic-control-type = "bl_ctrl_pwm";
            qcom,mdss-dsi-bllp-eof-power-mode;
            qcom,mdss-dsi-bllp-power-mode;
            qcom,mdss-dsi-border-color = <0x0>;
            qcom,mdss-dsi-bpp = <0x18>;
            qcom,mdss-dsi-color-order = "rgb_swap_rgb";
            qcom,mdss-dsi-dma-trigger = "trigger_sw";
            qcom,mdss-dsi-h-sync-pulse = <0x0>;
            qcom,mdss-dsi-lane-0-state;
            qcom,mdss-dsi-lane-1-state;
            qcom,mdss-dsi-lane-2-state;
            qcom,mdss-dsi-lane-3-state;
            qcom,mdss-dsi-lane-map = "lane_map_0123";
            qcom,mdss-dsi-lp11-init;
            qcom,mdss-dsi-mdp-trigger = "none";
            qcom,mdss-dsi-panel-mode-switch;
            qcom,mdss-dsi-panel-name = "td4330 v2 cmd mode dsi truly panel";
            qcom,mdss-dsi-panel-on-check-value = <0x1C>;
            qcom,mdss-dsi-panel-status-check-mode = "reg_read";
            qcom,mdss-dsi-panel-status-command = <0x6010001 0x10A>;
            qcom,mdss-dsi-panel-status-command-state = "dsi_hs_mode";
            qcom,mdss-dsi-panel-status-read-length = <0x1>;
            qcom,mdss-dsi-panel-status-value = <0x1C>;
            qcom,mdss-dsi-panel-type = "dsi_cmd_mode";
            qcom,mdss-dsi-reset-sequence = <0x1 0xA 0x0 0xA 0x1 0xA>;
            qcom,mdss-dsi-stream = <0x0>;
            qcom,mdss-dsi-te-check-enable;
            qcom,mdss-dsi-te-dcs-command = <0x1>;
            qcom,mdss-dsi-te-pin-select = <0x1>;
            qcom,mdss-dsi-te-using-te-pin;
            qcom,mdss-dsi-traffic-mode = "non_burst_sync_event";
            qcom,mdss-dsi-tx-eot-append;
            qcom,mdss-dsi-underflow-color = <0xFF>;
            qcom,mdss-dsi-virtual-channel-id = <0x0>;
            qcom,mdss-dsi-wr-mem-continue = <0x3C>;
            qcom,mdss-dsi-wr-mem-start = <0x2C>;
            qcom,panel-supply-entries = <&dsi_panel_pwr_supply_no_labibb>;
            qcom,platform-reset-gpio = <&tlmm 0x52 0x0>;
            qcom,platform-te-gpio = <&tlmm 0x51 0x0>;
            qcom,ulps-enabled;
            qcom,mdss-dsi-display-timings {
                timing@0 {
                    qcom,default-topology-index = <0x0>;
                    qcom,display-topology = <0x1 0x0 0x1>;
                    qcom,dsi-dyn-clk-list = <0x38491AB0 0x3758F3D0 0x3794FD88 0x37D10740 0x380D10F0>;
                    qcom,mdss-dsi-cmd-mode;
                    qcom,mdss-dsi-h-back-porch = <0x50>;
                    qcom,mdss-dsi-h-front-porch = <0x50>;
                    qcom,mdss-dsi-h-pulse-width = <0x14>;
                    qcom,mdss-dsi-h-sync-skew = <0x0>;
                    qcom,mdss-dsi-off-command = [05 01 00 00 32 00 02 28 00 05 01 00 00 96 00 02 10 00];
                    qcom,mdss-dsi-off-command-state = "dsi_hs_mode";
                    qcom,mdss-dsi-on-command = [29 01 00 00 00 00 02 B0 00 29 01 00 00 00 00 0D B6 30 6B 00 06 03 0A 13 1A 6C 18 19 02 29 01 00 00 00 00 05 B7 40 00 00 00 29 01 00 00 00 00 08 B8 57 3D 19 BE 1E 0A 0A 29 01 00 00 00 00 08 B9 6F 3D 28 BE 3C 14 0A 29 01 00 00 00 00 08 BA B5 33 41 BE 64 23 0A 29 01 00 00 00 00 0C BB 44 26 C3 1F 19 06 03 C0 00 00 10 29 01 00 00 00 00 0C BC 32 4C C3 52 32 1F 03 F2 00 00 13 29 01 00 00 00 00 0C BD 24 68 C3 AA 3F 32 03 FF 00 00 25 29 01 00 00 00 00 0D BE 00 00 00 00 00 00 00 00 00 00 00 00 29 01 00 00 00 00 0D C0 00 DC 00 DC 04 08 E8 00 04 00 03 78 29 01 00 00 00 00 24 C1 30 00 00 11 11 00 00 00 22 00 05 20 FA 00 08 00 00 00 00 00 00 00 00 00 00 00 00 00 00 00 00 00 00 00 00 29 01 00 00 00 00 79 C2 06 E0 6E 01 03 00 02 00 00 00 00 00 00 00 00 00 00 00 00 00 00 00 00 00 00 00 00 00 00 00 00 00 00 00 00 00 00 00 00 00 00 11 00 00 00 00 04 A0 C9 00 00 00 00 00 00 48 EB 00 00 01 00 00 00 11 00 00 00 00 00 00 00 00 00 00 00 00 00 00 00 00 00 00 00 00 11 00 00 00 00 00 00 DC 00 00 00 00 04 00 08 EF 00 00 00 00 00 11 00 00 00 00 00 00 00 00 00 00 00 00 00 00 29 01 00 00 00 00 6D C3 00 00 00 00 00 00 00 00 00 00 00 00 00 00 00 00 00 00 00 00 00 00 00 00 00 00 00 00 00 00 00 00 00 00 00 00 00 00 00 00 00 00 00 00 00 00 00 00 00 00 00 00 00 00 00 00 00 00 00 00 00 00 AA AA AA 00 00 00 00 00 00 00 00 00 00 00 00 00 00 00 00 00 00 00 00 00 00 00 00 00 00 00 00 00 00 00 00 00 00 00 00 00 00 00 00 00 00 00 29 01 00 00 00 00 62 C4 00 4C 00 3F 00 83 00 00 87 86 85 84 00 00 00 00 00 61 5D 5F 00 5E 60 62 00 00 00 02 00 83 00 00 87 86 85 84 00 00 00 00 00 61 5D 5F 00 5E 60 62 FF FF FF FF FF FF 00 0F 0E 00 0F 0E 00 00 00 00 00 00 00 0F EE 00 0F EE 00 00 E0 00 00 E0 0E 00 00 00 0E 00 00 00 00 00 FF 57 00 00 00 00 00 00 00 29 01 00 00 00 00 06 C5 08 00 00 00 00 29 01 00 00 00 00 3A C6 02 0A 08 FC FF FF FF 00 00 13 01 F0 0C 06 01 43 43 43 00 00 00 01 77 09 28 28 06 01 43 43 43 00 00 00 01 61 00 00 00 1C 01 00 00 00 00 00 00 00 00 00 00 00 00 20 20 00 00 29 01 00 00 00 00 4D C7 00 00 00 E0 01 E9 02 7E 02 05 02 90 02 F6 02 40 02 5C 02 77 02 C8 02 1B 02 5B 02 BD 02 27 02 C3 03 54 03 D8 03 FF 00 00 00 E0 01 E9 02 7E 02 05 02 90 02 F6 02 40 02 5C 02 77 02 C8 02 1B 02 5B 02 BD 02 27 02 C3 03 54 03 D8 03 FF 29 01 00 00 00 00 42 C8 41 00 FF FA 00 FF 00 00 FE F6 FE E9 00 00 FF F7 FB E1 00 00 00 00 00 FF 00 00 FF FA 00 FF 00 FE F6 FE E9 00 FF F7 FB E1 00 00 00 00 FF 00 FF FA 00 FF 00 FE F6 FE E9 00 FF F7 FB E1 00 00 00 00 FF 29 01 00 00 00 00 19 C9 00 FF FA 00 FF 00 00 FE F6 FE E9 00 00 FF F7 FB E1 00 00 00 00 00 FF 00 29 01 00 00 00 00 42 CA 1C FC FC FC 00 00 00 00 00 00 00 00 00 00 00 00 00 00 00 00 00 00 00 00 00 00 00 00 00 00 00 00 00 00 00 00 00 00 00 00 00 00 00 00 00 00 00 00 00 00 00 00 00 00 00 00 00 00 00 00 00 00 00 00 00 29 01 00 00 00 00 0B CC 00 00 4D 8B 55 4D 8B AA 4D 8B 29 01 00 00 00 00 02 CD 00 29 01 00 00 00 00 24 CE 5D 40 49 53 59 5E 63 68 6E 74 7E 8A 98 A8 BB D0 E7 FF 04 00 04 04 42 04 69 5A 40 11 F4 00 00 84 FA 00 00 29 01 00 00 00 00 07 CF 00 00 80 46 61 00 29 01 00 00 00 00 12 D0 F6 95 11 B1 55 CF 00 F6 D3 11 F0 01 12 CF 02 20 11 29 01 00 00 00 00 23 D1 D3 D3 33 33 07 03 3B 33 77 37 77 37 35 77 07 77 F7 33 73 07 33 33 03 33 1B 03 32 3D 0A 30 13 13 20 00 29 01 00 00 00 00 05 D2 00 00 07 00 29 01 00 00 00 00 9A D3 03 00 00 00 00 00 00 0F 00 57 00 00 32 00 00 1A 70 01 19 80 01 01 F0 02 00 E0 06 FF F7 FF FF F7 FF FF F7 FF FF F7 FF FF F7 FF FF F7 FF FF F7 FF FF F7 FF FF F7 FF FF F7 FF FF F7 FF FF F7 FF FF F7 FF FF F7 FF FF F7 FF FF F7 FF FF F7 FF FF F7 FF FF F7 FF FF F7 FF FF F7 FF FF F7 FF FF F7 FF FF F7 FF FF F7 FF FF F7 FF FF F7 FF FF F7 FF FF F7 FF FF F7 FF FF F7 FF FF F7 FF FF F7 FF FF F7 FF FF F7 FF FF F7 FF FF F7 FF FF F7 FF FF F7 FF FF F7 FF FF F7 FF FF F7 FF 29 01 00 00 00 00 05 E5 03 00 00 00 29 01 00 00 00 00 09 D5 02 42 02 42 02 DC 02 DC 29 01 00 00 00 00 02 D6 C0 29 01 00 00 00 00 32 D7 21 10 52 52 00 B6 04 FD 00 B6 04 FD 00 82 80 83 84 85 83 80 84 45 85 85 85 87 04 06 02 04 04 07 10 0C 0B 0A 0A 07 06 00 08 00 00 00 00 00 00 00 00 29 01 00 00 00 00 05 DD 30 06 23 65 29 01 00 00 00 00 0D DE 00 00 00 0F FF 00 00 00 00 00 00 10 29 01 00 00 00 00 02 E3 FF 29 01 00 00 00 00 07 E6 00 00 00 00 00 00 29 01 00 00 00 00 0B E7 50 04 00 00 00 00 00 00 00 00 29 01 00 00 00 00 05 E8 00 01 23 00 29 01 00 00 00 00 1E EA 01 02 47 80 47 00 00 00 05 00 13 60 02 47 80 47 00 00 00 00 13 60 00 11 00 30 10 21 02 29 01 00 00 00 00 08 EB 00 00 00 00 01 00 11 29 01 00 00 00 00 04 EC 00 00 00 29 01 00 00 00 00 21 ED 01 01 02 02 02 02 00 00 00 00 00 00 0A 00 00 00 00 10 00 18 00 18 00 B0 00 00 00 00 00 DA 10 00 29 01 00 00 00 00 61 EE 03 0F 00 00 00 00 40 1F 00 00 0F F2 3F 00 00 00 00 00 00 00 00 00 00 00 00 00 00 00 10 01 00 09 01 8C D8 EF 00 00 00 00 00 00 00 00 00 00 00 00 00 00 00 00 00 00 50 1F 00 00 00 00 00 00 00 00 00 00 00 00 00 00 00 00 00 00 00 00 00 00 00 00 00 00 00 00 00 00 00 00 00 00 00 00 00 00 00 00 29 01 00 00 00 00 8C EF 00 70 4A 08 D0 00 00 00 00 3C 3C 3C 00 00 00 00 00 00 00 00 00 00 00 00 00 00 00 00 70 4A 08 D0 00 00 00 00 3C 3C 3C 00 00 00 00 00 00 00 00 00 00 00 00 00 00 00 00 00 00 00 00 00 00 00 00 00 00 00 00 00 00 00 00 00 00 00 00 00 00 00 00 00 00 00 00 00 00 00 00 00 00 00 00 00 03 08 EC 50 10 00 10 00 0A 0A 00 00 00 00 10 0F 00 03 51 00 50 00 00 00 00 00 00 00 00 00 00 00 00 00 00 00 00 00 00 00 00 00 00 00 03 08 EC 29 01 00 00 00 00 02 B0 03 29 01 00 00 00 00 02 B0 04 29 01 00 00 00 00 02 D6 00 39 01 00 00 00 00 03 51 FF F0 39 01 00 00 00 00 02 53 0C 39 01 00 00 00 00 02 55 00 39 01 00 00 00 00 02 35 00 39 01 00 00 00 00 05 2A 00 00 04 37 39 01 00 00 00 00 05 2B 00 00 08 E7 05 01 00 00 FF 00 02 29 00 05 01 00 00 FF 00 02 11 00];
                    qcom,mdss-dsi-on-command-state = "dsi_lp_mode";
                    qcom,mdss-dsi-panel-framerate = <0x3C>;
                    qcom,mdss-dsi-panel-height = <0x8E8>;
                    qcom,mdss-dsi-panel-jitter = <0x4 0x1>;
                    qcom,mdss-dsi-panel-phy-timings = [00 23 09 09 26 24 09 09 09 02 04 00 1E 19];
                    qcom,mdss-dsi-panel-width = <0x438>;
                    qcom,mdss-dsi-v-back-porch = <0xD>;
                    qcom,mdss-dsi-v-front-porch = <0x10>;
                    qcom,mdss-dsi-v-pulse-width = <0x2>;
                    qcom,panel-roi-alignment = <0x28 0x28 0x28 0x28 0x28 0x28>;
                    qcom,partial-update-enabled = "single_roi";
                    qcom,video-to-cmd-mode-post-switch-commands = [15 01 00 00 00 00 02 B0 00 29 01 00 00 00 00 05 B7 40 00 00 00];
                    qcom,video-to-cmd-mode-post-switch-commands-state = "dsi_lp_mode";
                };
                timing@1 {
                    qcom,cmd-to-video-mode-post-switch-commands = [15 01 00 00 00 00 02 B0 00 29 01 00 00 00 00 05 B7 51 00 00 00];
                    qcom,cmd-to-video-mode-post-switch-commands-state = "dsi_lp_mode";
                    qcom,default-topology-index = <0x0>;
                    qcom,display-topology = <0x1 0x0 0x1>;
                    qcom,dsi-dyn-clk-list = <0x38491AB0 0x3758F3D0 0x3794FD88 0x37D10740 0x380D10F0>;
                    qcom,mdss-dsi-h-back-porch = <0x28>;
                    qcom,mdss-dsi-h-front-porch = <0x28>;
                    qcom,mdss-dsi-h-pulse-width = <0x14>;
                    qcom,mdss-dsi-h-sync-skew = <0x0>;
                    qcom,mdss-dsi-off-command = [05 01 00 00 32 00 02 28 00 05 01 00 00 96 00 02 10 00];
                    qcom,mdss-dsi-off-command-state = "dsi_hs_mode";
                    qcom,mdss-dsi-on-command = [29 01 00 00 00 00 02 B0 00 29 01 00 00 00 00 0D B6 30 6B 00 06 03 0A 13 1A 6C 18 19 02 29 01 00 00 00 00 05 B7 51 00 00 00 29 01 00 00 00 00 08 B8 57 3D 19 BE 1E 0A 0A 29 01 00 00 00 00 08 B9 6F 3D 28 BE 3C 14 0A 29 01 00 00 00 00 08 BA B5 33 41 BE 64 23 0A 29 01 00 00 00 00 0C BB 44 26 C3 1F 19 06 03 C0 00 00 10 29 01 00 00 00 00 0C BC 32 4C C3 52 32 1F 03 F2 00 00 13 29 01 00 00 00 00 0C BD 24 68 C3 AA 3F 32 03 FF 00 00 25 29 01 00 00 00 00 0D BE 00 00 00 00 00 00 00 00 00 00 00 00 29 01 00 00 00 00 0D C0 00 DC 00 DC 04 08 E8 00 04 00 03 78 29 01 00 00 00 00 24 C1 30 00 00 11 11 00 00 00 22 00 05 20 FA 00 08 00 00 00 00 00 00 00 00 00 00 00 00 00 00 00 00 00 00 00 00 29 01 00 00 00 00 79 C2 06 E0 6E 01 03 00 02 00 00 00 00 00 00 00 00 00 00 00 00 00 00 00 00 00 00 00 00 00 00 00 00 00 00 00 00 00 00 00 00 00 00 11 00 00 00 00 04 A0 C9 00 00 00 00 00 00 48 EB 00 00 01 00 00 00 11 00 00 00 00 00 00 00 00 00 00 00 00 00 00 00 00 00 00 00 00 11 00 00 00 00 00 00 DC 00 00 00 00 04 00 08 EF 00 00 00 00 00 11 00 00 00 00 00 00 00 00 00 00 00 00 00 00 29 01 00 00 00 00 6D C3 00 00 00 00 00 00 00 00 00 00 00 00 00 00 00 00 00 00 00 00 00 00 00 00 00 00 00 00 00 00 00 00 00 00 00 00 00 00 00 00 00 00 00 00 00 00 00 00 00 00 00 00 00 00 00 00 00 00 00 00 00 00 AA AA AA 00 00 00 00 00 00 00 00 00 00 00 00 00 00 00 00 00 00 00 00 00 00 00 00 00 00 00 00 00 00 00 00 00 00 00 00 00 00 00 00 00 00 00 29 01 00 00 00 00 62 C4 00 4C 00 3F 00 83 00 00 87 86 85 84 00 00 00 00 00 61 5D 5F 00 5E 60 62 00 00 00 02 00 83 00 00 87 86 85 84 00 00 00 00 00 61 5D 5F 00 5E 60 62 FF FF FF FF FF FF 00 0F 0E 00 0F 0E 00 00 00 00 00 00 00 0F EE 00 0F EE 00 00 E0 00 00 E0 0E 00 00 00 0E 00 00 00 00 00 FF 57 00 00 00 00 00 00 00 29 01 00 00 00 00 06 C5 08 00 00 00 00 29 01 00 00 00 00 3A C6 02 0A 08 FC FF FF FF 00 00 13 01 F0 0C 06 01 43 43 43 00 00 00 01 77 09 28 28 06 01 43 43 43 00 00 00 01 61 00 00 00 1C 01 00 00 00 00 00 00 00 00 00 00 00 00 20 20 00 00 29 01 00 00 00 00 4D C7 00 00 00 E0 01 E9 02 7E 02 05 02 90 02 F6 02 40 02 5C 02 77 02 C8 02 1B 02 5B 02 BD 02 27 02 C3 03 54 03 D8 03 FF 00 00 00 E0 01 E9 02 7E 02 05 02 90 02 F6 02 40 02 5C 02 77 02 C8 02 1B 02 5B 02 BD 02 27 02 C3 03 54 03 D8 03 FF 29 01 00 00 00 00 42 C8 41 00 FF FA 00 FF 00 00 FE F6 FE E9 00 00 FF F7 FB E1 00 00 00 00 00 FF 00 00 FF FA 00 FF 00 FE F6 FE E9 00 FF F7 FB E1 00 00 00 00 FF 00 FF FA 00 FF 00 FE F6 FE E9 00 FF F7 FB E1 00 00 00 00 FF 29 01 00 00 00 00 19 C9 00 FF FA 00 FF 00 00 FE F6 FE E9 00 00 FF F7 FB E1 00 00 00 00 00 FF 00 29 01 00 00 00 00 42 CA 1C FC FC FC 00 00 00 00 00 00 00 00 00 00 00 00 00 00 00 00 00 00 00 00 00 00 00 00 00 00 00 00 00 00 00 00 00 00 00 00 00 00 00 00 00 00 00 00 00 00 00 00 00 00 00 00 00 00 00 00 00 00 00 00 00 29 01 00 00 00 00 0B CC 00 00 4D 8B 55 4D 8B AA 4D 8B 29 01 00 00 00 00 02 CD 00 29 01 00 00 00 00 24 CE 5D 40 49 53 59 5E 63 68 6E 74 7E 8A 98 A8 BB D0 E7 FF 04 00 04 04 42 04 69 5A 40 11 F4 00 00 84 FA 00 00 29 01 00 00 00 00 07 CF 00 00 80 46 61 00 29 01 00 00 00 00 12 D0 F6 95 11 B1 55 CF 00 F6 D3 11 F0 01 12 CF 02 20 11 29 01 00 00 00 00 23 D1 D3 D3 33 33 07 03 3B 33 77 37 77 37 35 77 07 77 F7 33 73 07 33 33 03 33 1B 03 32 3D 0A 30 13 13 20 00 29 01 00 00 00 00 05 D2 00 00 07 00 29 01 00 00 00 00 9A D3 03 00 00 00 00 00 00 0F 00 57 00 00 32 00 00 1A 70 01 19 80 01 01 F0 02 00 E0 06 FF F7 FF FF F7 FF FF F7 FF FF F7 FF FF F7 FF FF F7 FF FF F7 FF FF F7 FF FF F7 FF FF F7 FF FF F7 FF FF F7 FF FF F7 FF FF F7 FF FF F7 FF FF F7 FF FF F7 FF FF F7 FF FF F7 FF FF F7 FF FF F7 FF FF F7 FF FF F7 FF FF F7 FF FF F7 FF FF F7 FF FF F7 FF FF F7 FF FF F7 FF FF F7 FF FF F7 FF FF F7 FF FF F7 FF FF F7 FF FF F7 FF FF F7 FF FF F7 FF FF F7 FF FF F7 FF FF F7 FF FF F7 FF FF F7 FF 29 01 00 00 00 00 05 E5 03 00 00 00 29 01 00 00 00 00 09 D5 02 42 02 42 02 DC 02 DC 29 01 00 00 00 00 02 D6 C0 29 01 00 00 00 00 32 D7 21 10 52 52 00 B6 04 FD 00 B6 04 FD 00 82 80 83 84 85 83 80 84 45 85 85 85 87 04 06 02 04 04 07 10 0C 0B 0A 0A 07 06 00 08 00 00 00 00 00 00 00 00 29 01 00 00 00 00 05 DD 30 06 23 65 29 01 00 00 00 00 0D DE 00 00 00 0F FF 00 00 00 00 00 00 10 29 01 00 00 00 00 02 E3 FF 29 01 00 00 00 00 07 E6 00 00 00 00 00 00 29 01 00 00 00 00 0B E7 50 04 00 00 00 00 00 00 00 00 29 01 00 00 00 00 05 E8 00 01 23 00 29 01 00 00 00 00 1E EA 01 02 47 80 47 00 00 00 05 00 12 60 02 47 80 47 00 00 00 00 13 60 00 11 00 30 10 21 02 29 01 00 00 00 00 08 EB 00 00 00 00 01 00 11 29 01 00 00 00 00 04 EC 00 00 00 29 01 00 00 00 00 21 ED 01 01 02 02 02 02 00 00 00 00 00 00 0A 00 00 00 00 10 00 18 00 18 00 B0 00 00 00 00 00 DA 10 00 29 01 00 00 00 00 61 EE 03 0F 00 00 00 00 40 1F 00 00 0F F2 3F 00 00 00 00 00 00 00 00 00 00 00 00 00 00 00 10 01 00 09 01 8C D8 EF 00 00 00 00 00 00 00 00 00 00 00 00 00 00 00 00 00 00 50 1F 00 00 00 00 00 00 00 00 00 00 00 00 00 00 00 00 00 00 00 00 00 00 00 00 00 00 00 00 00 00 00 00 00 00 00 00 00 00 00 00 29 01 00 00 00 00 8C EF 00 70 4A 08 D0 00 00 00 00 3C 3C 3C 00 00 00 00 00 00 00 00 00 00 00 00 00 00 00 00 70 4A 08 D0 00 00 00 00 3C 3C 3C 00 00 00 00 00 00 00 00 00 00 00 00 00 00 00 00 00 00 00 00 00 00 00 00 00 00 00 00 00 00 00 00 00 00 00 00 00 00 00 00 00 00 00 00 00 00 00 00 00 00 00 00 00 03 08 EC 50 10 00 10 00 0A 0A 00 00 00 00 10 0F 00 03 51 00 50 00 00 00 00 00 00 00 00 00 00 00 00 00 00 00 00 00 00 00 00 00 00 00 03 08 EC 29 01 00 00 00 00 02 B0 03 29 01 00 00 00 00 02 B0 04 29 01 00 00 00 00 02 D6 00 39 01 00 00 00 00 03 51 FF F0 39 01 00 00 00 00 02 53 0C 39 01 00 00 00 00 02 55 00 39 01 00 00 00 00 02 35 00 39 01 00 00 00 00 05 2A 00 00 04 37 39 01 00 00 00 00 05 2B 00 00 08 E7 05 01 00 00 FF 00 02 29 00 05 01 00 00 FF 00 02 11 00];
                    qcom,mdss-dsi-on-command-state = "dsi_lp_mode";
                    qcom,mdss-dsi-panel-framerate = <0x3C>;
                    qcom,mdss-dsi-panel-height = <0x8E8>;
                    qcom,mdss-dsi-panel-phy-timings = [00 21 08 08 25 22 09 08 09 02 04 00 1D 18];
                    qcom,mdss-dsi-panel-width = <0x438>;
                    qcom,mdss-dsi-v-back-porch = <0x6>;
                    qcom,mdss-dsi-v-front-porch = <0xA>;
                    qcom,mdss-dsi-v-pulse-width = <0x2>;
                    qcom,mdss-dsi-video-mode;
                };
            };
        };
        qcom,mdss_dsi_td4330_truly_v2_video {
            pwms = <&pm6125_pwm 0x0 0x0>;
            qcom,bl-pmic-pwm-period-usecs = <0x64>;
            qcom,dsi-ctrl-num = <0x0>;
            qcom,dsi-dyn-clk-enable;
            qcom,dsi-dyn-clk-list = <0x3A2F7BC0 0x3AE9AD50 0x3AAB9CC8 0x3A6D8C48>;
            qcom,dsi-dyn-clk-type = "constant-fps-adjust-vfp";
            qcom,dsi-phy-num = <0x0>;
            qcom,dsi-select-clocks = "pll_byte_clk0", "pll_dsi_clk0";
            qcom,dsi-supported-dfps-list = <0x3C 0x37 0x30>;
            qcom,mdss-dsi-bl-max-level = <0xFFF>;
            qcom,mdss-dsi-bl-min-level = <0x1>;
            qcom,mdss-dsi-bl-pmic-control-type = "bl_ctrl_pwm";
            qcom,mdss-dsi-bllp-eof-power-mode;
            qcom,mdss-dsi-bllp-power-mode;
            qcom,mdss-dsi-border-color = <0x0>;
            qcom,mdss-dsi-bpp = <0x18>;
            qcom,mdss-dsi-color-order = "rgb_swap_rgb";
            qcom,mdss-dsi-dma-trigger = "trigger_sw";
            qcom,mdss-dsi-h-left-border = <0x0>;
            qcom,mdss-dsi-h-right-border = <0x0>;
            qcom,mdss-dsi-h-sync-pulse = <0x0>;
            qcom,mdss-dsi-lane-0-state;
            qcom,mdss-dsi-lane-1-state;
            qcom,mdss-dsi-lane-2-state;
            qcom,mdss-dsi-lane-3-state;
            qcom,mdss-dsi-lane-map = "lane_map_0123";
            qcom,mdss-dsi-lp11-init;
            qcom,mdss-dsi-mdp-trigger = "none";
            qcom,mdss-dsi-pan-enable-dynamic-fps;
            qcom,mdss-dsi-pan-fps-update = "dfps_immediate_porch_mode_vfp";
            qcom,mdss-dsi-panel-mode-switch;
            qcom,mdss-dsi-panel-name = "td4330 v2 video mode dsi truly panel";
            qcom,mdss-dsi-panel-on-check-value = <0x1C>;
            qcom,mdss-dsi-panel-status-check-mode = "reg_read";
            qcom,mdss-dsi-panel-status-command = <0x6010001 0x10A>;
            qcom,mdss-dsi-panel-status-command-state = "dsi_hs_mode";
            qcom,mdss-dsi-panel-status-read-length = <0x1>;
            qcom,mdss-dsi-panel-status-value = <0x1C>;
            qcom,mdss-dsi-panel-type = "dsi_video_mode";
            qcom,mdss-dsi-reset-sequence = <0x1 0xA 0x0 0xA 0x1 0xA>;
            qcom,mdss-dsi-stream = <0x0>;
            qcom,mdss-dsi-te-check-enable;
            qcom,mdss-dsi-te-dcs-command = <0x1>;
            qcom,mdss-dsi-te-pin-select = <0x1>;
            qcom,mdss-dsi-te-using-te-pin;
            qcom,mdss-dsi-traffic-mode = "non_burst_sync_event";
            qcom,mdss-dsi-tx-eot-append;
            qcom,mdss-dsi-underflow-color = <0xFF>;
            qcom,mdss-dsi-v-bottom-border = <0x0>;
            qcom,mdss-dsi-v-top-border = <0x0>;
            qcom,mdss-dsi-virtual-channel-id = <0x0>;
            qcom,mdss-dsi-wr-mem-continue = <0x3C>;
            qcom,mdss-dsi-wr-mem-start = <0x2C>;
            qcom,mdss-pan-physical-height-dimension = <0x81>;
            qcom,mdss-pan-physical-width-dimension = <0x41>;
            qcom,panel-supply-entries = <&dsi_panel_pwr_supply_no_labibb>;
            qcom,platform-reset-gpio = <&tlmm 0x52 0x0>;
            qcom,mdss-dsi-display-timings {
                timing@0 {
                    qcom,cmd-to-video-mode-post-switch-commands = [15 01 00 00 00 00 02 B0 00 29 01 00 00 00 00 05 B7 51 00 00 00];
                    qcom,cmd-to-video-mode-post-switch-commands-state = "dsi_lp_mode";
                    qcom,default-topology-index = <0x0>;
                    qcom,display-topology = <0x1 0x0 0x1>;
                    qcom,dsi-dyn-clk-list = <0x3A2F7BC0 0x3AE9AD50 0x3AAB9CC8 0x3A6D8C48>;
                    qcom,mdss-dsi-h-back-porch = <0x28>;
                    qcom,mdss-dsi-h-front-porch = <0x28>;
                    qcom,mdss-dsi-h-pulse-width = <0x14>;
                    qcom,mdss-dsi-h-sync-skew = <0x0>;
                    qcom,mdss-dsi-off-command = [05 01 00 00 32 00 02 28 00 05 01 00 00 96 00 02 10 00];
                    qcom,mdss-dsi-off-command-state = "dsi_hs_mode";
                    qcom,mdss-dsi-on-command = [29 01 00 00 00 00 02 B0 00 29 01 00 00 00 00 0D B6 30 6B 00 06 03 0A 13 1A 6C 18 19 02 29 01 00 00 00 00 05 B7 51 00 00 00 29 01 00 00 00 00 08 B8 57 3D 19 BE 1E 0A 0A 29 01 00 00 00 00 08 B9 6F 3D 28 BE 3C 14 0A 29 01 00 00 00 00 08 BA B5 33 41 BE 64 23 0A 29 01 00 00 00 00 0C BB 44 26 C3 1F 19 06 03 C0 00 00 10 29 01 00 00 00 00 0C BC 32 4C C3 52 32 1F 03 F2 00 00 13 29 01 00 00 00 00 0C BD 24 68 C3 AA 3F 32 03 FF 00 00 25 29 01 00 00 00 00 0D BE 00 00 00 00 00 00 00 00 00 00 00 00 29 01 00 00 00 00 0D C0 00 DC 00 DC 04 08 E8 00 04 00 03 78 29 01 00 00 00 00 24 C1 30 00 00 11 11 00 00 00 22 00 05 20 FA 00 08 00 00 00 00 00 00 00 00 00 00 00 00 00 00 00 00 00 00 00 00 29 01 00 00 00 00 79 C2 06 E0 6E 01 03 00 02 00 00 00 00 00 00 00 00 00 00 00 00 00 00 00 00 00 00 00 00 00 00 00 00 00 00 00 00 00 00 00 00 00 00 11 00 00 00 00 04 A0 C9 00 00 00 00 00 00 48 EB 00 00 01 00 00 00 11 00 00 00 00 00 00 00 00 00 00 00 00 00 00 00 00 00 00 00 00 11 00 00 00 00 00 00 DC 00 00 00 00 04 00 08 EF 00 00 00 00 00 11 00 00 00 00 00 00 00 00 00 00 00 00 00 00 29 01 00 00 00 00 6D C3 00 00 00 00 00 00 00 00 00 00 00 00 00 00 00 00 00 00 00 00 00 00 00 00 00 00 00 00 00 00 00 00 00 00 00 00 00 00 00 00 00 00 00 00 00 00 00 00 00 00 00 00 00 00 00 00 00 00 00 00 00 00 AA AA AA 00 00 00 00 00 00 00 00 00 00 00 00 00 00 00 00 00 00 00 00 00 00 00 00 00 00 00 00 00 00 00 00 00 00 00 00 00 00 00 00 00 00 00 29 01 00 00 00 00 62 C4 00 4C 00 3F 00 83 00 00 87 86 85 84 00 00 00 00 00 61 5D 5F 00 5E 60 62 00 00 00 02 00 83 00 00 87 86 85 84 00 00 00 00 00 61 5D 5F 00 5E 60 62 FF FF FF FF FF FF 00 0F 0E 00 0F 0E 00 00 00 00 00 00 00 0F EE 00 0F EE 00 00 E0 00 00 E0 0E 00 00 00 0E 00 00 00 00 00 FF 57 00 00 00 00 00 00 00 29 01 00 00 00 00 06 C5 08 00 00 00 00 29 01 00 00 00 00 3A C6 02 0A 08 FC FF FF FF 00 00 13 01 F0 0C 06 01 43 43 43 00 00 00 01 77 09 28 28 06 01 43 43 43 00 00 00 01 61 00 00 00 1C 01 00 00 00 00 00 00 00 00 00 00 00 00 20 20 00 00 29 01 00 00 00 00 4D C7 00 00 00 E0 01 E9 02 7E 02 05 02 90 02 F6 02 40 02 5C 02 77 02 C8 02 1B 02 5B 02 BD 02 27 02 C3 03 54 03 D8 03 FF 00 00 00 E0 01 E9 02 7E 02 05 02 90 02 F6 02 40 02 5C 02 77 02 C8 02 1B 02 5B 02 BD 02 27 02 C3 03 54 03 D8 03 FF 29 01 00 00 00 00 42 C8 41 00 FF FA 00 FF 00 00 FE F6 FE E9 00 00 FF F7 FB E1 00 00 00 00 00 FF 00 00 FF FA 00 FF 00 FE F6 FE E9 00 FF F7 FB E1 00 00 00 00 FF 00 FF FA 00 FF 00 FE F6 FE E9 00 FF F7 FB E1 00 00 00 00 FF 29 01 00 00 00 00 19 C9 00 FF FA 00 FF 00 00 FE F6 FE E9 00 00 FF F7 FB E1 00 00 00 00 00 FF 00 29 01 00 00 00 00 42 CA 1C FC FC FC 00 00 00 00 00 00 00 00 00 00 00 00 00 00 00 00 00 00 00 00 00 00 00 00 00 00 00 00 00 00 00 00 00 00 00 00 00 00 00 00 00 00 00 00 00 00 00 00 00 00 00 00 00 00 00 00 00 00 00 00 00 29 01 00 00 00 00 0B CC 00 00 4D 8B 55 4D 8B AA 4D 8B 29 01 00 00 00 00 02 CD 00 29 01 00 00 00 00 24 CE 5D 40 49 53 59 5E 63 68 6E 74 7E 8A 98 A8 BB D0 E7 FF 04 00 04 04 42 04 69 5A 40 11 F4 00 00 84 FA 00 00 29 01 00 00 00 00 07 CF 00 00 80 46 61 00 29 01 00 00 00 00 12 D0 F6 95 11 B1 55 CF 00 F6 D3 11 F0 01 12 CF 02 20 11 29 01 00 00 00 00 23 D1 D3 D3 33 33 07 03 3B 33 77 37 77 37 35 77 07 77 F7 33 73 07 33 33 03 33 1B 03 32 3D 0A 30 13 13 20 00 29 01 00 00 00 00 05 D2 00 00 07 00 29 01 00 00 00 00 9A D3 03 00 00 00 00 00 00 0F 00 57 00 00 32 00 00 1A 70 01 19 80 01 01 F0 02 00 E0 06 FF F7 FF FF F7 FF FF F7 FF FF F7 FF FF F7 FF FF F7 FF FF F7 FF FF F7 FF FF F7 FF FF F7 FF FF F7 FF FF F7 FF FF F7 FF FF F7 FF FF F7 FF FF F7 FF FF F7 FF FF F7 FF FF F7 FF FF F7 FF FF F7 FF FF F7 FF FF F7 FF FF F7 FF FF F7 FF FF F7 FF FF F7 FF FF F7 FF FF F7 FF FF F7 FF FF F7 FF FF F7 FF FF F7 FF FF F7 FF FF F7 FF FF F7 FF FF F7 FF FF F7 FF FF F7 FF FF F7 FF FF F7 FF FF F7 FF 29 01 00 00 00 00 05 E5 03 00 00 00 29 01 00 00 00 00 09 D5 02 42 02 42 02 DC 02 DC 29 01 00 00 00 00 02 D6 C0 29 01 00 00 00 00 32 D7 21 10 52 52 00 B6 04 FD 00 B6 04 FD 00 82 80 83 84 85 83 80 84 45 85 85 85 87 04 06 02 04 04 07 10 0C 0B 0A 0A 07 06 00 08 00 00 00 00 00 00 00 00 29 01 00 00 00 00 05 DD 30 06 23 65 29 01 00 00 00 00 0D DE 00 00 00 0F FF 00 00 00 00 00 00 10 29 01 00 00 00 00 02 E3 FF 29 01 00 00 00 00 07 E6 00 00 00 00 00 00 29 01 00 00 00 00 0B E7 50 04 00 00 00 00 00 00 00 00 29 01 00 00 00 00 05 E8 00 01 23 00 29 01 00 00 00 00 1E EA 01 02 47 80 47 00 00 00 05 00 12 60 02 47 80 47 00 00 00 00 13 60 00 11 00 30 10 21 02 29 01 00 00 00 00 08 EB 00 00 00 00 01 00 11 29 01 00 00 00 00 04 EC 00 00 00 29 01 00 00 00 00 21 ED 01 01 02 02 02 02 00 00 00 00 00 00 0A 00 00 00 00 10 00 18 00 18 00 B0 00 00 00 00 00 DA 10 00 29 01 00 00 00 00 61 EE 03 0F 00 00 00 00 40 1F 00 00 0F F2 3F 00 00 00 00 00 00 00 00 00 00 00 00 00 00 00 10 01 00 09 01 8C D8 EF 00 00 00 00 00 00 00 00 00 00 00 00 00 00 00 00 00 00 50 1F 00 00 00 00 00 00 00 00 00 00 00 00 00 00 00 00 00 00 00 00 00 00 00 00 00 00 00 00 00 00 00 00 00 00 00 00 00 00 00 00 29 01 00 00 00 00 8C EF 00 70 4A 08 D0 00 00 00 00 3C 3C 3C 00 00 00 00 00 00 00 00 00 00 00 00 00 00 00 00 70 4A 08 D0 00 00 00 00 3C 3C 3C 00 00 00 00 00 00 00 00 00 00 00 00 00 00 00 00 00 00 00 00 00 00 00 00 00 00 00 00 00 00 00 00 00 00 00 00 00 00 00 00 00 00 00 00 00 00 00 00 00 00 00 00 00 03 08 EC 50 10 00 10 00 0A 0A 00 00 00 00 10 0F 00 03 51 00 50 00 00 00 00 00 00 00 00 00 00 00 00 00 00 00 00 00 00 00 00 00 00 00 03 08 EC 29 01 00 00 00 00 02 B0 03 29 01 00 00 00 00 02 B0 04 29 01 00 00 00 00 02 D6 00 39 01 00 00 00 00 03 51 FF F0 39 01 00 00 00 00 02 53 0C 39 01 00 00 00 00 02 55 00 39 01 00 00 00 00 02 35 00 39 01 00 00 00 00 05 2A 00 00 04 37 39 01 00 00 00 00 05 2B 00 00 08 E7 05 01 00 00 FF 00 02 29 00 05 01 00 00 FF 00 02 11 00];
                    qcom,mdss-dsi-on-command-state = "dsi_lp_mode";
                    qcom,mdss-dsi-panel-framerate = <0x3C>;
                    qcom,mdss-dsi-panel-height = <0x8E8>;
                    qcom,mdss-dsi-panel-phy-timings = [00 21 08 08 25 22 09 08 09 02 04 00 1D 18];
                    qcom,mdss-dsi-panel-width = <0x438>;
                    qcom,mdss-dsi-v-back-porch = <0x6>;
                    qcom,mdss-dsi-v-front-porch = <0xA>;
                    qcom,mdss-dsi-v-pulse-width = <0x2>;
                    qcom,mdss-dsi-video-mode;
                };
                timing@1 {
                    qcom,default-topology-index = <0x0>;
                    qcom,display-topology = <0x1 0x0 0x1>;
                    qcom,dsi-dyn-clk-list = <0x3A2F7BC0 0x3AE9AD50 0x3AAB9CC8 0x3A6D8C48>;
                    qcom,mdss-dsi-cmd-mode;
                    qcom,mdss-dsi-h-back-porch = <0x50>;
                    qcom,mdss-dsi-h-front-porch = <0x50>;
                    qcom,mdss-dsi-h-pulse-width = <0x14>;
                    qcom,mdss-dsi-h-sync-skew = <0x0>;
                    qcom,mdss-dsi-off-command = [05 01 00 00 32 00 02 28 00 05 01 00 00 96 00 02 10 00];
                    qcom,mdss-dsi-off-command-state = "dsi_hs_mode";
                    qcom,mdss-dsi-on-command = [29 01 00 00 00 00 02 B0 00 29 01 00 00 00 00 0D B6 30 6B 00 06 03 0A 13 1A 6C 18 19 02 29 01 00 00 00 00 05 B7 40 00 00 00 29 01 00 00 00 00 08 B8 57 3D 19 BE 1E 0A 0A 29 01 00 00 00 00 08 B9 6F 3D 28 BE 3C 14 0A 29 01 00 00 00 00 08 BA B5 33 41 BE 64 23 0A 29 01 00 00 00 00 0C BB 44 26 C3 1F 19 06 03 C0 00 00 10 29 01 00 00 00 00 0C BC 32 4C C3 52 32 1F 03 F2 00 00 13 29 01 00 00 00 00 0C BD 24 68 C3 AA 3F 32 03 FF 00 00 25 29 01 00 00 00 00 0D BE 00 00 00 00 00 00 00 00 00 00 00 00 29 01 00 00 00 00 0D C0 00 DC 00 DC 04 08 E8 00 04 00 03 78 29 01 00 00 00 00 24 C1 30 00 00 11 11 00 00 00 22 00 05 20 FA 00 08 00 00 00 00 00 00 00 00 00 00 00 00 00 00 00 00 00 00 00 00 29 01 00 00 00 00 79 C2 06 E0 6E 01 03 00 02 00 00 00 00 00 00 00 00 00 00 00 00 00 00 00 00 00 00 00 00 00 00 00 00 00 00 00 00 00 00 00 00 00 00 11 00 00 00 00 04 A0 C9 00 00 00 00 00 00 48 EB 00 00 01 00 00 00 11 00 00 00 00 00 00 00 00 00 00 00 00 00 00 00 00 00 00 00 00 11 00 00 00 00 00 00 DC 00 00 00 00 04 00 08 EF 00 00 00 00 00 11 00 00 00 00 00 00 00 00 00 00 00 00 00 00 29 01 00 00 00 00 6D C3 00 00 00 00 00 00 00 00 00 00 00 00 00 00 00 00 00 00 00 00 00 00 00 00 00 00 00 00 00 00 00 00 00 00 00 00 00 00 00 00 00 00 00 00 00 00 00 00 00 00 00 00 00 00 00 00 00 00 00 00 00 00 AA AA AA 00 00 00 00 00 00 00 00 00 00 00 00 00 00 00 00 00 00 00 00 00 00 00 00 00 00 00 00 00 00 00 00 00 00 00 00 00 00 00 00 00 00 00 29 01 00 00 00 00 62 C4 00 4C 00 3F 00 83 00 00 87 86 85 84 00 00 00 00 00 61 5D 5F 00 5E 60 62 00 00 00 02 00 83 00 00 87 86 85 84 00 00 00 00 00 61 5D 5F 00 5E 60 62 FF FF FF FF FF FF 00 0F 0E 00 0F 0E 00 00 00 00 00 00 00 0F EE 00 0F EE 00 00 E0 00 00 E0 0E 00 00 00 0E 00 00 00 00 00 FF 57 00 00 00 00 00 00 00 29 01 00 00 00 00 06 C5 08 00 00 00 00 29 01 00 00 00 00 3A C6 02 0A 08 FC FF FF FF 00 00 13 01 F0 0C 06 01 43 43 43 00 00 00 01 77 09 28 28 06 01 43 43 43 00 00 00 01 61 00 00 00 1C 01 00 00 00 00 00 00 00 00 00 00 00 00 20 20 00 00 29 01 00 00 00 00 4D C7 00 00 00 E0 01 E9 02 7E 02 05 02 90 02 F6 02 40 02 5C 02 77 02 C8 02 1B 02 5B 02 BD 02 27 02 C3 03 54 03 D8 03 FF 00 00 00 E0 01 E9 02 7E 02 05 02 90 02 F6 02 40 02 5C 02 77 02 C8 02 1B 02 5B 02 BD 02 27 02 C3 03 54 03 D8 03 FF 29 01 00 00 00 00 42 C8 41 00 FF FA 00 FF 00 00 FE F6 FE E9 00 00 FF F7 FB E1 00 00 00 00 00 FF 00 00 FF FA 00 FF 00 FE F6 FE E9 00 FF F7 FB E1 00 00 00 00 FF 00 FF FA 00 FF 00 FE F6 FE E9 00 FF F7 FB E1 00 00 00 00 FF 29 01 00 00 00 00 19 C9 00 FF FA 00 FF 00 00 FE F6 FE E9 00 00 FF F7 FB E1 00 00 00 00 00 FF 00 29 01 00 00 00 00 42 CA 1C FC FC FC 00 00 00 00 00 00 00 00 00 00 00 00 00 00 00 00 00 00 00 00 00 00 00 00 00 00 00 00 00 00 00 00 00 00 00 00 00 00 00 00 00 00 00 00 00 00 00 00 00 00 00 00 00 00 00 00 00 00 00 00 00 29 01 00 00 00 00 0B CC 00 00 4D 8B 55 4D 8B AA 4D 8B 29 01 00 00 00 00 02 CD 00 29 01 00 00 00 00 24 CE 5D 40 49 53 59 5E 63 68 6E 74 7E 8A 98 A8 BB D0 E7 FF 04 00 04 04 42 04 69 5A 40 11 F4 00 00 84 FA 00 00 29 01 00 00 00 00 07 CF 00 00 80 46 61 00 29 01 00 00 00 00 12 D0 F6 95 11 B1 55 CF 00 F6 D3 11 F0 01 12 CF 02 20 11 29 01 00 00 00 00 23 D1 D3 D3 33 33 07 03 3B 33 77 37 77 37 35 77 07 77 F7 33 73 07 33 33 03 33 1B 03 32 3D 0A 30 13 13 20 00 29 01 00 00 00 00 05 D2 00 00 07 00 29 01 00 00 00 00 9A D3 03 00 00 00 00 00 00 0F 00 57 00 00 32 00 00 1A 70 01 19 80 01 01 F0 02 00 E0 06 FF F7 FF FF F7 FF FF F7 FF FF F7 FF FF F7 FF FF F7 FF FF F7 FF FF F7 FF FF F7 FF FF F7 FF FF F7 FF FF F7 FF FF F7 FF FF F7 FF FF F7 FF FF F7 FF FF F7 FF FF F7 FF FF F7 FF FF F7 FF FF F7 FF FF F7 FF FF F7 FF FF F7 FF FF F7 FF FF F7 FF FF F7 FF FF F7 FF FF F7 FF FF F7 FF FF F7 FF FF F7 FF FF F7 FF FF F7 FF FF F7 FF FF F7 FF FF F7 FF FF F7 FF FF F7 FF FF F7 FF FF F7 FF FF F7 FF 29 01 00 00 00 00 05 E5 03 00 00 00 29 01 00 00 00 00 09 D5 02 42 02 42 02 DC 02 DC 29 01 00 00 00 00 02 D6 C0 29 01 00 00 00 00 32 D7 21 10 52 52 00 B6 04 FD 00 B6 04 FD 00 82 80 83 84 85 83 80 84 45 85 85 85 87 04 06 02 04 04 07 10 0C 0B 0A 0A 07 06 00 08 00 00 00 00 00 00 00 00 29 01 00 00 00 00 05 DD 30 06 23 65 29 01 00 00 00 00 0D DE 00 00 00 0F FF 00 00 00 00 00 00 10 29 01 00 00 00 00 02 E3 FF 29 01 00 00 00 00 07 E6 00 00 00 00 00 00 29 01 00 00 00 00 0B E7 50 04 00 00 00 00 00 00 00 00 29 01 00 00 00 00 05 E8 00 01 23 00 29 01 00 00 00 00 1E EA 01 02 47 80 47 00 00 00 05 00 13 60 02 47 80 47 00 00 00 00 13 60 00 11 00 30 10 21 02 29 01 00 00 00 00 08 EB 00 00 00 00 01 00 11 29 01 00 00 00 00 04 EC 00 00 00 29 01 00 00 00 00 21 ED 01 01 02 02 02 02 00 00 00 00 00 00 0A 00 00 00 00 10 00 18 00 18 00 B0 00 00 00 00 00 DA 10 00 29 01 00 00 00 00 61 EE 03 0F 00 00 00 00 40 1F 00 00 0F F2 3F 00 00 00 00 00 00 00 00 00 00 00 00 00 00 00 10 01 00 09 01 8C D8 EF 00 00 00 00 00 00 00 00 00 00 00 00 00 00 00 00 00 00 50 1F 00 00 00 00 00 00 00 00 00 00 00 00 00 00 00 00 00 00 00 00 00 00 00 00 00 00 00 00 00 00 00 00 00 00 00 00 00 00 00 00 29 01 00 00 00 00 8C EF 00 70 4A 08 D0 00 00 00 00 3C 3C 3C 00 00 00 00 00 00 00 00 00 00 00 00 00 00 00 00 70 4A 08 D0 00 00 00 00 3C 3C 3C 00 00 00 00 00 00 00 00 00 00 00 00 00 00 00 00 00 00 00 00 00 00 00 00 00 00 00 00 00 00 00 00 00 00 00 00 00 00 00 00 00 00 00 00 00 00 00 00 00 00 00 00 00 03 08 EC 50 10 00 10 00 0A 0A 00 00 00 00 10 0F 00 03 51 00 50 00 00 00 00 00 00 00 00 00 00 00 00 00 00 00 00 00 00 00 00 00 00 00 03 08 EC 29 01 00 00 00 00 02 B0 03 29 01 00 00 00 00 02 B0 04 29 01 00 00 00 00 02 D6 00 39 01 00 00 00 00 03 51 FF F0 39 01 00 00 00 00 02 53 0C 39 01 00 00 00 00 02 55 00 39 01 00 00 00 00 02 35 00 39 01 00 00 00 00 05 2A 00 00 04 37 39 01 00 00 00 00 05 2B 00 00 08 E7 05 01 00 00 FF 00 02 29 00 05 01 00 00 FF 00 02 11 00];
                    qcom,mdss-dsi-on-command-state = "dsi_lp_mode";
                    qcom,mdss-dsi-panel-framerate = <0x3C>;
                    qcom,mdss-dsi-panel-height = <0x8E8>;
                    qcom,mdss-dsi-panel-jitter = <0x4 0x1>;
                    qcom,mdss-dsi-panel-phy-timings = [00 23 09 09 26 24 09 09 09 02 04 00 1E 19];
                    qcom,mdss-dsi-panel-width = <0x438>;
                    qcom,mdss-dsi-v-back-porch = <0xD>;
                    qcom,mdss-dsi-v-front-porch = <0x10>;
                    qcom,mdss-dsi-v-pulse-width = <0x2>;
                    qcom,video-to-cmd-mode-post-switch-commands = [15 01 00 00 00 00 02 B0 00 29 01 00 00 00 00 05 B7 40 00 00 00];
                    qcom,video-to-cmd-mode-post-switch-commands-state = "dsi_lp_mode";
                };
            };
        };
        qcom,platform-supply-entries {
            #address-cells = <0x1>;
            #size-cells = <0x0>;
            qcom,platform-supply-entry@0 {
                qcom,supply-disable-load = <0x0>;
                qcom,supply-enable-load = <0x0>;
                qcom,supply-max-voltage = <0x0>;
                qcom,supply-min-voltage = <0x0>;
                qcom,supply-name = "sde-vdd";
                reg = <0x0>;
            };
        };
        qcom,sde-dspp-blocks {
            qcom,sde-dspp-dither = <0x82C 0x10007>;
            qcom,sde-dspp-gc = <0x17C0 0x10008>;
            qcom,sde-dspp-hist = <0x800 0x10007>;
            qcom,sde-dspp-hsic = <0x800 0x10007>;
            qcom,sde-dspp-igc = <0x0 0x30001>;
            qcom,sde-dspp-memcolor = <0x880 0x10007>;
            qcom,sde-dspp-pcc = <0x1700 0x40000>;
            qcom,sde-dspp-sixzone = <0x900 0x10007>;
            qcom,sde-dspp-vlut = <0xA00 0x10008>;
        };
        qcom,sde-limits {
            qcom,sde-bw-limits {
                qcom,sde-limit-cases = "per_vig_pipe", "per_dma_pipe", "total_max_bw", "camera_concurrency";
                qcom,sde-limit-ids = <0x1 0x2 0x4 0x8>;
                qcom,sde-limit-name = "sde_bwlimit_usecases";
                qcom,sde-limit-values = <0x1 0x30D400 0x9 0x30D400 0x2 0x30D400 0xA 0x30D400 0x4 0x419CE0 0xC 0x30D400>;
            };
            qcom,sde-linewidth-limits {
                qcom,sde-limit-cases = "vig", "dma", "scale";
                qcom,sde-limit-ids = <0x1 0x2 0x4>;
                qcom,sde-limit-name = "sspp_linewidth_usecases";
                qcom,sde-limit-values = <0x1 0x1000 0x5 0xA00 0x2 0x870>;
            };
        };
        qcom,sde-sspp-vig-blocks {
            qcom,sde-vig-csc-off = <0x1A00>;
            qcom,sde-vig-inverse-pma;
            qcom,sde-vig-qseed-off = <0xA00>;
            qcom,sde-vig-qseed-size = <0xA0>;
        };
    };
    qcom,mdss_rotator {
        #list-cells = <0x1>;
        clock-names = "gcc_iface", "iface_clk", "rot_clk";
        clocks = <&gcc 0x3C &dispcc 0x0 &dispcc 0xE>;
        compatible = "qcom,sde_rotator";
        interconnect-names = "qcom,rot-data-bus0", "qcom,sde-reg-bus";
        interconnects = <&mmrt_virt 0xE &bimc 0x200 &bimc 0x0 &config_noc 0x212>;
        interrupt-parent = <&mdss_mdp>;
        interrupts = <0x2 0x0>;
        power-domains = <&mdss_mdp>;
        qcom,mdss-default-ot-rd-limit = <0x20>;
        qcom,mdss-default-ot-wr-limit = <0x20>;
        qcom,mdss-rot-cdp-setting = <0x1 0x1>;
        qcom,mdss-rot-danger-lut = <0x0 0x0>;
        qcom,mdss-rot-mode = <0x1>;
        qcom,mdss-rot-parent = <&mdss_mdp 0x0>;
        qcom,mdss-rot-qos-lut = <0x0 0x0 0x0 0x0>;
        qcom,mdss-rot-safe-lut = <0xFFFF 0xFFFF>;
        qcom,mdss-rot-vbif-qos-setting = <0x3 0x3 0x3 0x3 0x3 0x3 0x3 0x3>;
        qcom,mdss-rot-xin-id = <0xA 0xB>;
        qcom,mdss-sbuf-headroom = <0x14>;
        qcom,msm-bus,name = "mdss_rotator";
        qcom,msm-bus,num-cases = <0x3>;
        qcom,msm-bus,num-paths = <0x1>;
        qcom,msm-bus,vectors-KBps = <0x16 0x200 0x0 0x0 0x16 0x200 0x0 0x61A800 0x16 0x200 0x0 0x61A800>;
        qcom,sde-reg-bus,vectors-KBps = <0x0 0x0 0x0 0x12C00>;
        qcom,supply-names = "rot-vdd";
        reg = <0x5E00000 0xAC000 0x5EB0000 0x2008>;
        reg-names = "mdp_phys", "rot_vbif_phys";
        rot-vdd-supply = <&mdss_core_gdsc>;
        qcom,smmu_rot_sec_cb {
            compatible = "qcom,smmu_sde_rot_sec";
            iommus = <&apps_smmu 0x43D 0x0>;
            qcom,iommu-dma-addr-pool = <0x20000 0xFFFE0000>;
            qcom,iommu-faults = "non-fatal";
            qcom,iommu-vmid = <0xA>;
        };
        qcom,smmu_rot_unsec_cb {
            compatible = "qcom,smmu_sde_rot_unsec";
            iommus = <&apps_smmu 0x43C 0x0>;
            qcom,iommu-dma-addr-pool = <0x20000 0xFFFE0000>;
            qcom,iommu-faults = "non-fatal";
        };
    };
    qcom,msm_notifier@0 {
        compatible = "qcom,msm-notifier";
    };
    qcom,nopmi-chg {
        #io-channel-cells = <0x1>;
        compatible = "qcom,nopmi-chg";
        enable_sw_jeita;
        io-channel-names = "resistance_id", "shutdown_delay", "soc_decimal", "soc_decimal_rate", "fastcharge_mode", "fg_batt_id", "charge_type", "charge_enabled", "charge_ic_type", "charge_pd_active", "sc_bus_current", "charging_enabled", "sc_chip_id", "cc_chip_id", "ds_chip_id", "ds_chip_ok", "ds_authen_result";
        io-channels = <&sm5602 0x4B &sm5602 0xA1 &sm5602 0xA2 &sm5602 0xA3 &sm5602 0xA4 &sm5602 0xAD &bq2589x 0x74 &bq2589x 0xA0 &bq2589x 0xAA &bq2589x 0x4 &sc8551_standalone 0x9A &sc8551_standalone 0x76 &sc8551_standalone 0xA7 &rpm 0xA7 &maxim_ds28e16 0xA7 &maxim_ds28e16 0x8D &maxim_ds28e16 0x84>;
        jeita_temp_above_t4_cv = <0x1004>;
        jeita_temp_below_t0_cv = <0x1162>;
        jeita_temp_t0_to_t1_cv = <0x1162>;
        jeita_temp_t1_to_t1p5_cv = <0x1162>;
        jeita_temp_t1p5_to_t2_cv = <0x1162>;
        jeita_temp_t2_to_t3_cv = <0x1162>;
        jeita_temp_t3_to_t4_cv = <0x1004>;
        jeita_temp_tn1_to_t0_cv = <0x1162>;
        nopmi,thermal-mitigation = <0x5ACA30 0x5265C0 0x4C4B40 0x44AA20 0x3D0900 0x387520 0x3567E0 0x2DC6C0 0x2AB980 0x2625A0 0x1E8480 0x16E360 0xF4240 0xC3500 0x7A120 0x493E0>;
        qcom,fv-max-uv = <0x432380>;
        status = "okay";
        temp_neg_10_thres = <0xFFFFFFF6>;
        temp_t0_thres = <0x0>;
        temp_t0_thres_plus_x_degree = <0x1>;
        temp_t0_to_t1_fcc = <0x3B6>;
        temp_t1_thres = <0x5>;
        temp_t1_thres_plus_x_degree = <0x6>;
        temp_t1_to_t1p5_fcc = <0x960>;
        temp_t1p5_thres = <0xA>;
        temp_t1p5_thres_plus_x_degree = <0xB>;
        temp_t1p5_to_t2_fcc = <0xF3C>;
        temp_t2_thres = <0xF>;
        temp_t2_thres_plus_x_degree = <0x11>;
        temp_t2_to_t3_fcc = <0x173E>;
        temp_t3_thres = <0x30>;
        temp_t3_thres_minus_x_degree = <0x2E>;
        temp_t3_to_t4_fcc = <0x92E>;
        temp_t4_thres = <0x3C>;
        temp_t4_thres_minus_x_degree = <0x3A>;
        temp_tn1_thres = <0xFFFFFFF6>;
        temp_tn1_thres_plus_x_degree = <0xFFFFFFF7>;
        temp_tn1_to_t0_fcc = <0x1EA>;
    };
    qcom,smmu_sde_sec_cb {
        compatible = "qcom,smmu_sde_sec";
        iommus = <&apps_smmu 0x421 0x0>;
        qcom,iommu-dma-addr-pool = <0x20000 0xFFFE0000>;
        qcom,iommu-faults = "non-fatal";
        qcom,iommu-vmid = <0xA>;
    };
    qcom,smmu_sde_unsec_cb {
        compatible = "qcom,smmu_sde_unsec";
        iommus = <&apps_smmu 0x420 0x2>;
        qcom,iommu-dma-addr-pool = <0x20000 0xFFFE0000>;
        qcom,iommu-earlymap;
        qcom,iommu-faults = "non-fatal";
    };
    qcom,wb-display@0 {
        cell-index = <0x0>;
        compatible = "qcom,wb-display";
        label = "wb_display";
        status = "disabled";
    };
    qcom_cp_manager {
        compatible = "qcom,cp_manager";
        io-channel-names = "present", "charging_enabled", "status", "sc_battery_present", "sc_vbus_present", "sc_battery_voltage", "sc_battery_current", "sc_battery_temperature", "sc_bus_voltage", "sc_bus_current", "sc_bus_temperature", "sc_die_temperature", "sc_alarm_status", "sc_fault_status", "sc_vbus_error_status", "sc_chip_vendor", "sc_chip_id", "input_suspend", "pd_active", "battery_charging_enabled", "charge_enabled", "apdo_volt", "apdo_curr";
        io-channels = <&sc8551_standalone 0x92 &sc8551_standalone 0x76 &sc8551_standalone 0x91 &sc8551_standalone 0x94 &sc8551_standalone 0x95 &sc8551_standalone 0x96 &sc8551_standalone 0x97 &sc8551_standalone 0x98 &sc8551_standalone 0x99 &sc8551_standalone 0x9A &sc8551_standalone 0x9B &sc8551_standalone 0x9C &sc8551_standalone 0x9D &sc8551_standalone 0x93 &sc8551_standalone 0x9E &sc8551_standalone 0x9F &sc8551_standalone 0xA7 &nopmi_chg 0x78 &nopmi_chg 0x4 &nopmi_chg 0x76 &bq2589x 0xA0 &nopmi_chg 0xA8 &nopmi_chg 0xA9>;
        status = "okay";
    };
    rpm: rt-pd-manager {
        #io-channel-cells = <0x1>;
        compatible = "richtek,rt-pd-manager";
        io-channel-names = "usb_real_type", "pd_active", "pd_voltage_min", "pd_voltage_max", "pd_current_max", "typec_cc_orientation", "pd_usb_suspend_supported", "pd_in_hard_reset", "cc_chip_id";
        io-channels = <&nopmi_chg 0xA &nopmi_chg 0x4 &nopmi_chg 0xC &nopmi_chg 0xB &nopmi_chg 0x0 &nopmi_chg 0x3 &nopmi_chg 0x1F &nopmi_chg 0x1E &rpm 0xA7>;
    };
    thermal-message {
        board-sensor = "VIRTUAL-SENSOR";
    };
    thermal-screen {
        panel = <&dsi_panel_m7_38_0c_0a_fhdp_video &dsi_panel_m7_38_0c_0b_fhdp_video>;
    };
    vdda_usb_ss_dp_core {
        compatible = "regulator-fixed";
        enable-active-high;
        gpio = <&pm6125_gpios 0x1 0x0>;
        pinctrl-0 = <&usb_eldo9>;
        pinctrl-names = "default";
        regulator-max-microvolt = <0xD6D80>;
        regulator-min-microvolt = <0xD6D80>;
        regulator-name = "vdd_supply";
    };
    vibrator_gpio {
        compatible = "qcom,qpnp-vibrator-ldo-tz";
        pinctrl-0 = <&vib_out_gpio8_default>;
        pinctrl-names = "default";
        status = "ok";
        vib,en-gpio = <&pm6125_gpios 0x8 0x1>;
    };
    xiaomi_touch {
        compatible = "xiaomi-touch";
        status = "okay";
        touch,name = "xiaomi-touch";
    };
    xm_pd_adapter {
        adapter_name = "pd_adapter";
        compatible = "xiaomi,pd_adapter";
    };
};

&thermal_zones {
    pm6125-tz {
        cooling-maps {
            trip0_cpu0 {
                cooling-device = <&CPU0 0x7 0x7>;
                trip = <&pm6125_trip0>;
            };
            trip0_cpu4 {
                cooling-device = <&CPU4 0x6 0xFFFFFFFF>;
                trip = <&pm6125_trip0>;
            };
            trip1_cpu1 {
                cooling-device = <&cpu1_pause 0x1 0x1>;
                trip = <&pm6125_trip1>;
            };
            trip1_cpu2 {
                cooling-device = <&cpu2_pause 0x1 0x1>;
                trip = <&pm6125_trip1>;
            };
            trip1_cpu3 {
                cooling-device = <&cpu3_pause 0x1 0x1>;
                trip = <&pm6125_trip1>;
            };
            trip1_cpu4 {
                cooling-device = <&cpu4_pause 0x1 0x1>;
                trip = <&pm6125_trip1>;
            };
            trip1_cpu5 {
                cooling-device = <&cpu5_pause 0x1 0x1>;
                trip = <&pm6125_trip1>;
            };
            trip1_cpu6 {
                cooling-device = <&cpu6_pause 0x1 0x1>;
                trip = <&pm6125_trip1>;
            };
            trip1_cpu7 {
                cooling-device = <&cpu7_pause 0x1 0x1>;
                trip = <&pm6125_trip1>;
            };
        };
    };
    rf-pa1-therm-usr {
        polling-delay = <0x0>;
        polling-delay-passive = <0x0>;
        thermal-governor = "user_space";
        thermal-sensors = <&pm6125_adc_tm 0x3>;
        wake-capable-sensor;
        trips {
            active-config0 {
                hysteresis = <0x3E8>;
                temperature = <0x1E848>;
                type = "passive";
            };
        };
    };
};

&tlmm {
    bq2589x_int_default {
        config {
            bias-pull-up;
            drive-strength = <0x2>;
            input-enable;
            pins = "gpio105";
        };
        mux {
            function = "gpio";
            pins = "gpio105";
        };
    };
    bq2589x_usb_switch_default {
        config {
            bias-pull-down;
            drive-strength = <0x2>;
            output-low;
            pins = "gpio31";
        };
        mux {
            function = "gpio";
            pins = "gpio31";
        };
    };
    onewire_gpio_active {
        config {
            bias-pull-up;
            drive-strength = <0x2>;
            pins = "gpio108";
        };
        mux {
            function = "gpio";
            pins = "gpio108";
        };
    };
    onewire_gpio_sleep {
        config {
            bias-pull-up;
            drive-strength = <0x2>;
            pins = "gpio108";
        };
        mux {
            function = "gpio";
            pins = "gpio108";
        };
    };
    rt1711h_int_n: rt1711h_int_n {
        config {
            bias-pull-up;
            drive-strength = <0x2>;
            pins = "gpio93";
        };
        mux {
            function = "gpio";
            pins = "gpio93";
        };
    };
};

&ufshc_mem {
    qcom,vddp-ref-clk-max-microamp = <0x64>;
    qcom,vddp-ref-clk-supply = <&L18A>;
    reset-gpios = <&tlmm 0x71 0x1>;
    reset-names = "rst";
    resets = <&gcc 0x4>;
    status = "ok";
    vcc-max-microamp = <0xC3500>;
    vcc-supply = <&L24A>;
    vccq2-max-microamp = <0xC3500>;
    vccq2-supply = <&L11A>;
    vdd-hba-fixed-regulator;
    vdd-hba-supply = <&gcc_ufs_phy_gdsc>;
};

&ufsphy_mem {
    compatible = "qcom,ufs-phy-qmp-v4-khaje";
    status = "ok";
    vdda-phy-max-microamp = <0x14EC4>;
    vdda-phy-supply = <&L4A>;
    vdda-pll-max-microamp = <0x477C>;
    vdda-pll-supply = <&L18A>;
};

&usb0 {
    extcon = <&rpm &eud>;
};

&usb_qmp_dp_phy {
    vdd-supply = <&vdda_usb_ss_dp_core>;
};

